VERSION ""

NS_ :

BS_:

BU_:

BO_ 1025 ID_1025: 8 Vector__XXX
 SG_ electricalRPM_FL_erpm : 7|32@0+ (1,0) [0|4294967295] "rpm" Vector__XXX
 SG_ dutyCycle_FL_percent : 39|16@0+ (0.1,0) [0.0|6553.5] "%" Vector__XXX
 SG_ inputInverterVoltage_FL_V : 55|16@0+ (1,0) [0|65535] "V" Vector__XXX

BO_ 1057 ID_1057: 8 Vector__XXX
 SG_ motorCurrent_FL_Apk : 7|16@0+ (0.1,0) [0.0|6553.5] "A" Vector__XXX
 SG_ batteryCurrent_FL_A : 23|16@0+ (0.1,0) [0.0|6553.5] "A" Vector__XXX

BO_ 1089 ID_1089: 8 Vector__XXX
 SG_ controllerTemp_FL_C : 7|16@0+ (0.1,0) [0.0|6553.5] "C" Vector__XXX
 SG_ motorTemp_FL_C : 23|16@0+ (0.1,0) [0.0|6553.5] "C" Vector__XXX
 SG_ faultCode_FL : 39|8@0+ (1,0) [0|255] "" Vector__XXX

BO_ 1121 ID_1121: 8 Vector__XXX
 SG_ idPeak_FL_A : 7|32@0+ (0.01,0) [0.0|42949672.95] "A" Vector__XXX
 SG_ iqPeak_FL_A : 39|32@0+ (0.01,0) [0.0|42949672.95] "A" Vector__XXX

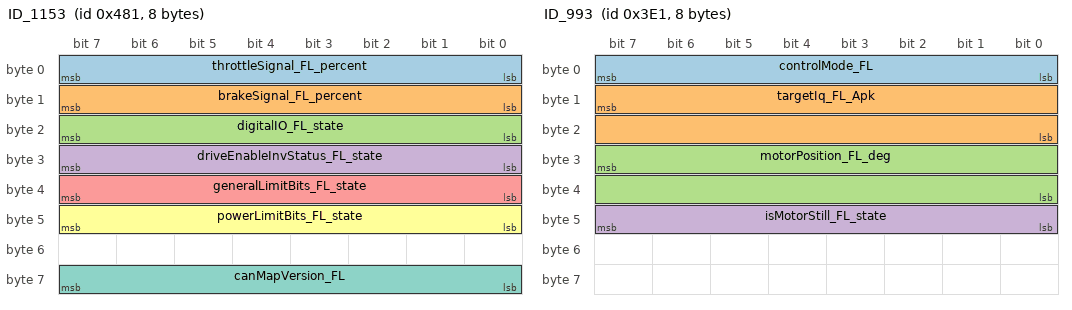
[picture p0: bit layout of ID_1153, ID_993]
BO_ 1153 ID_1153: 8 Vector__XXX
 SG_ throttleSignal_FL_percent : 7|8@0+ (1,0) [0|255] "%" Vector__XXX
 SG_ brakeSignal_FL_percent : 15|8@0+ (1,0) [0|255] "%" Vector__XXX
 SG_ digitalIO_FL_state : 23|8@0+ (1,0) [0|255] "" Vector__XXX
 SG_ driveEnableInvStatus_FL_state : 31|8@0+ (1,0) [0|255] "" Vector__XXX
 SG_ generalLimitBits_FL_state : 39|8@0+ (1,0) [0|255] "" Vector__XXX
 SG_ powerLimitBits_FL_state : 47|8@0+ (1,0) [0|255] "" Vector__XXX
 SG_ canMapVersion_FL : 63|8@0+ (1,0) [0|255] "" Vector__XXX

BO_ 993 ID_993: 8 Vector__XXX
 SG_ controlMode_FL : 7|8@0+ (1,0) [0|255] "" Vector__XXX
 SG_ targetIq_FL_Apk : 15|16@0+ (1,0) [0|65535] "Apk" Vector__XXX
 SG_ motorPosition_FL_deg : 31|16@0+ (1,0) [0|65535] "deg" Vector__XXX
 SG_ isMotorStill_FL_state : 47|8@0+ (1,0) [0|255] "" Vector__XXX

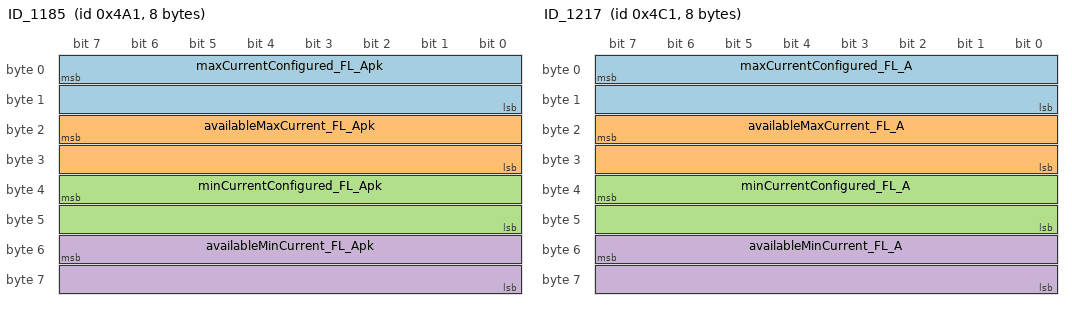
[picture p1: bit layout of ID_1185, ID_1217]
BO_ 1185 ID_1185: 8 Vector__XXX
 SG_ maxCurrentConfigured_FL_Apk : 7|16@0+ (0.1,0) [0.0|6553.5] "Apk" Vector__XXX
 SG_ availableMaxCurrent_FL_Apk : 23|16@0+ (0.1,0) [0.0|6553.5] "Apk" Vector__XXX
 SG_ minCurrentConfigured_FL_Apk : 39|16@0+ (0.1,0) [0.0|6553.5] "Apk" Vector__XXX
 SG_ availableMinCurrent_FL_Apk : 55|16@0+ (0.1,0) [0.0|6553.5] "Apk" Vector__XXX

BO_ 1217 ID_1217: 8 Vector__XXX
 SG_ maxCurrentConfigured_FL_A : 7|16@0+ (0.1,0) [0.0|6553.5] "A" Vector__XXX
 SG_ availableMaxCurrent_FL_A : 23|16@0+ (0.1,0) [0.0|6553.5] "A" Vector__XXX
 SG_ minCurrentConfigured_FL_A : 39|16@0+ (0.1,0) [0.0|6553.5] "A" Vector__XXX
 SG_ availableMinCurrent_FL_A : 55|16@0+ (0.1,0) [0.0|6553.5] "A" Vector__XXX

BO_ 33 ID_33: 8 Vector__XXX
 SG_ invCurrentCmd_FL_Apk : 7|16@0+ (0.1,0) [0.0|6553.5] "A" Vector__XXX

BO_ 257 ID_257: 8 Vector__XXX
 SG_ invMaxCurrentLimitCmd_FL_Apk : 7|16@0+ (0.1,0) [0.0|6553.5] "A" Vector__XXX

BO_ 321 ID_321: 8 Vector__XXX
 SG_ invMaxDCCurrentLimitCmd_FL_A : 7|16@0+ (0.1,0) [0.0|6553.5] "A" Vector__XXX

BO_ 385 ID_385: 8 Vector__XXX
 SG_ invDriveEnable_FL_state : 7|8@0+ (1,0) [0|255] "A" Vector__XXX

BO_ 1026 ID_1026: 8 Vector__XXX
 SG_ electricalRPM_FR_erpm : 7|32@0+ (1,0) [0|4294967295] "rpm" Vector__XXX
 SG_ dutyCycle_FR_percent : 39|16@0+ (0.1,0) [0.0|6553.5] "%" Vector__XXX
 SG_ inputInverterVoltage_FR_V : 55|16@0+ (1,0) [0|65535] "V" Vector__XXX

BO_ 1058 ID_1058: 8 Vector__XXX
 SG_ motorCurrent_FR_Apk : 7|16@0+ (0.1,0) [0.0|6553.5] "A" Vector__XXX
 SG_ batteryCurrent_FR_A : 23|16@0+ (0.1,0) [0.0|6553.5] "A" Vector__XXX

BO_ 1090 ID_1090: 8 Vector__XXX
 SG_ controllerTemp_FR_C : 7|16@0+ (0.1,0) [0.0|6553.5] "C" Vector__XXX
 SG_ motorTemp_FR_C : 23|16@0+ (0.1,0) [0.0|6553.5] "C" Vector__XXX
 SG_ faultCode_FR : 39|8@0+ (1,0) [0|255] "" Vector__XXX

BO_ 1122 ID_1122: 8 Vector__XXX
 SG_ idPeak_FR_A : 7|32@0+ (0.01,0) [0.0|42949672.95] "A" Vector__XXX
 SG_ iqPeak_FR_A : 39|32@0+ (0.01,0) [0.0|42949672.95] "A" Vector__XXX

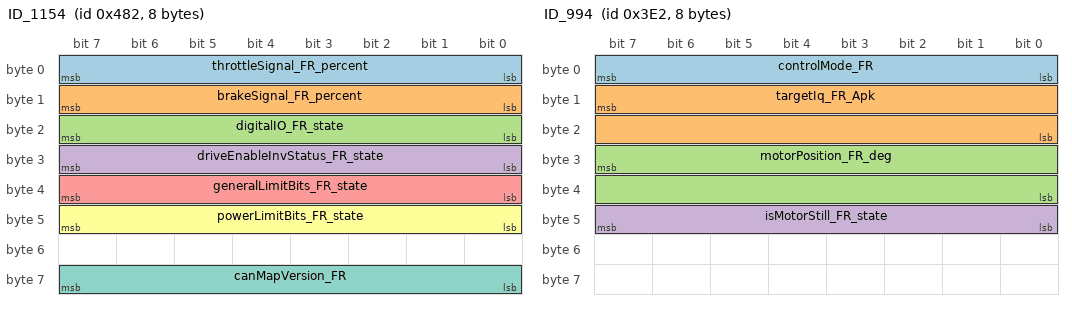
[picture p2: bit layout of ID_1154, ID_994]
BO_ 1154 ID_1154: 8 Vector__XXX
 SG_ throttleSignal_FR_percent : 7|8@0+ (1,0) [0|255] "%" Vector__XXX
 SG_ brakeSignal_FR_percent : 15|8@0+ (1,0) [0|255] "%" Vector__XXX
 SG_ digitalIO_FR_state : 23|8@0+ (1,0) [0|255] "" Vector__XXX
 SG_ driveEnableInvStatus_FR_state : 31|8@0+ (1,0) [0|255] "" Vector__XXX
 SG_ generalLimitBits_FR_state : 39|8@0+ (1,0) [0|255] "" Vector__XXX
 SG_ powerLimitBits_FR_state : 47|8@0+ (1,0) [0|255] "" Vector__XXX
 SG_ canMapVersion_FR : 63|8@0+ (1,0) [0|255] "" Vector__XXX

BO_ 994 ID_994: 8 Vector__XXX
 SG_ controlMode_FR : 7|8@0+ (1,0) [0|255] "" Vector__XXX
 SG_ targetIq_FR_Apk : 15|16@0+ (1,0) [0|65535] "Apk" Vector__XXX
 SG_ motorPosition_FR_deg : 31|16@0+ (1,0) [0|65535] "deg" Vector__XXX
 SG_ isMotorStill_FR_state : 47|8@0+ (1,0) [0|255] "" Vector__XXX

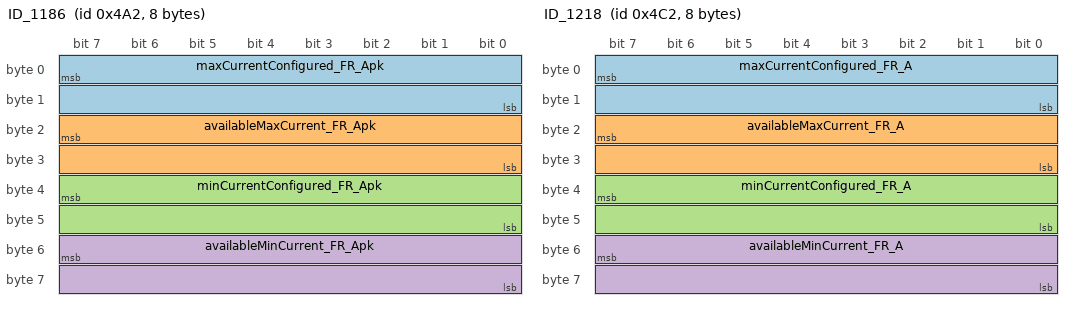
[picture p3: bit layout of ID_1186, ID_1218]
BO_ 1186 ID_1186: 8 Vector__XXX
 SG_ maxCurrentConfigured_FR_Apk : 7|16@0+ (0.1,0) [0.0|6553.5] "Apk" Vector__XXX
 SG_ availableMaxCurrent_FR_Apk : 23|16@0+ (0.1,0) [0.0|6553.5] "Apk" Vector__XXX
 SG_ minCurrentConfigured_FR_Apk : 39|16@0+ (0.1,0) [0.0|6553.5] "Apk" Vector__XXX
 SG_ availableMinCurrent_FR_Apk : 55|16@0+ (0.1,0) [0.0|6553.5] "Apk" Vector__XXX

BO_ 1218 ID_1218: 8 Vector__XXX
 SG_ maxCurrentConfigured_FR_A : 7|16@0+ (0.1,0) [0.0|6553.5] "A" Vector__XXX
 SG_ availableMaxCurrent_FR_A : 23|16@0+ (0.1,0) [0.0|6553.5] "A" Vector__XXX
 SG_ minCurrentConfigured_FR_A : 39|16@0+ (0.1,0) [0.0|6553.5] "A" Vector__XXX
 SG_ availableMinCurrent_FR_A : 55|16@0+ (0.1,0) [0.0|6553.5] "A" Vector__XXX

BO_ 34 ID_34: 8 Vector__XXX
 SG_ invCurrentCmd_FR_Apk : 7|16@0+ (0.1,0) [0.0|6553.5] "A" Vector__XXX

BO_ 258 ID_258: 8 Vector__XXX
 SG_ invMaxCurrentLimitCmd_FR_Apk : 7|16@0+ (0.1,0) [0.0|6553.5] "A" Vector__XXX

BO_ 322 ID_322: 8 Vector__XXX
 SG_ invMaxDCCurrentLimitCmd_FR_A : 7|16@0+ (0.1,0) [0.0|6553.5] "A" Vector__XXX

BO_ 386 ID_386: 8 Vector__XXX
 SG_ invDriveEnable_FR_state : 7|8@0+ (1,0) [0|255] "A" Vector__XXX

BO_ 1027 ID_1027: 8 Vector__XXX
 SG_ electricalRPM_RL_erpm : 7|32@0+ (1,0) [0|4294967295] "rpm" Vector__XXX
 SG_ dutyCycle_RL_percent : 39|16@0+ (0.1,0) [0.0|6553.5] "%" Vector__XXX
 SG_ inputInverterVoltage_RL_V : 55|16@0+ (1,0) [0|65535] "V" Vector__XXX

BO_ 1059 ID_1059: 8 Vector__XXX
 SG_ motorCurrent_RL_Apk : 7|16@0+ (0.1,0) [0.0|6553.5] "A" Vector__XXX
 SG_ batteryCurrent_RL_A : 23|16@0+ (0.1,0) [0.0|6553.5] "A" Vector__XXX

BO_ 1091 ID_1091: 8 Vector__XXX
 SG_ controllerTemp_RL_C : 7|16@0+ (0.1,0) [0.0|6553.5] "C" Vector__XXX
 SG_ motorTemp_RL_C : 23|16@0+ (0.1,0) [0.0|6553.5] "C" Vector__XXX
 SG_ faultCode_RL : 39|8@0+ (1,0) [0|255] "" Vector__XXX

BO_ 1123 ID_1123: 8 Vector__XXX
 SG_ idPeak_RL_A : 7|32@0+ (0.01,0) [0.0|42949672.95] "A" Vector__XXX
 SG_ iqPeak_RL_A : 39|32@0+ (0.01,0) [0.0|42949672.95] "A" Vector__XXX

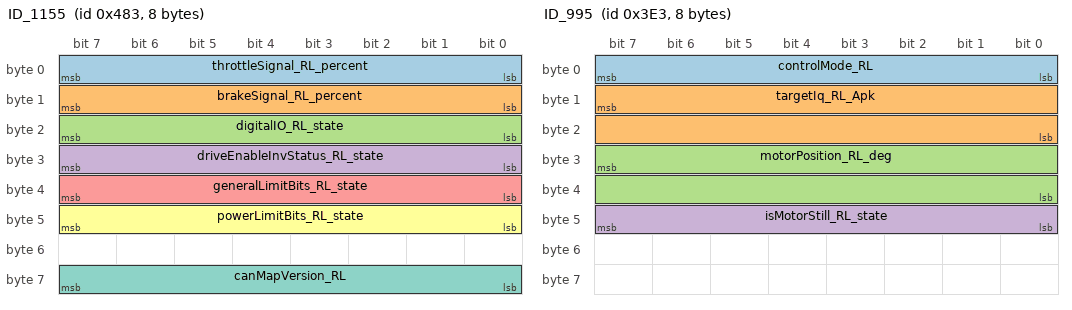
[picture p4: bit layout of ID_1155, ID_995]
BO_ 1155 ID_1155: 8 Vector__XXX
 SG_ throttleSignal_RL_percent : 7|8@0+ (1,0) [0|255] "%" Vector__XXX
 SG_ brakeSignal_RL_percent : 15|8@0+ (1,0) [0|255] "%" Vector__XXX
 SG_ digitalIO_RL_state : 23|8@0+ (1,0) [0|255] "" Vector__XXX
 SG_ driveEnableInvStatus_RL_state : 31|8@0+ (1,0) [0|255] "" Vector__XXX
 SG_ generalLimitBits_RL_state : 39|8@0+ (1,0) [0|255] "" Vector__XXX
 SG_ powerLimitBits_RL_state : 47|8@0+ (1,0) [0|255] "" Vector__XXX
 SG_ canMapVersion_RL : 63|8@0+ (1,0) [0|255] "" Vector__XXX

BO_ 995 ID_995: 8 Vector__XXX
 SG_ controlMode_RL : 7|8@0+ (1,0) [0|255] "" Vector__XXX
 SG_ targetIq_RL_Apk : 15|16@0+ (1,0) [0|65535] "Apk" Vector__XXX
 SG_ motorPosition_RL_deg : 31|16@0+ (1,0) [0|65535] "deg" Vector__XXX
 SG_ isMotorStill_RL_state : 47|8@0+ (1,0) [0|255] "" Vector__XXX

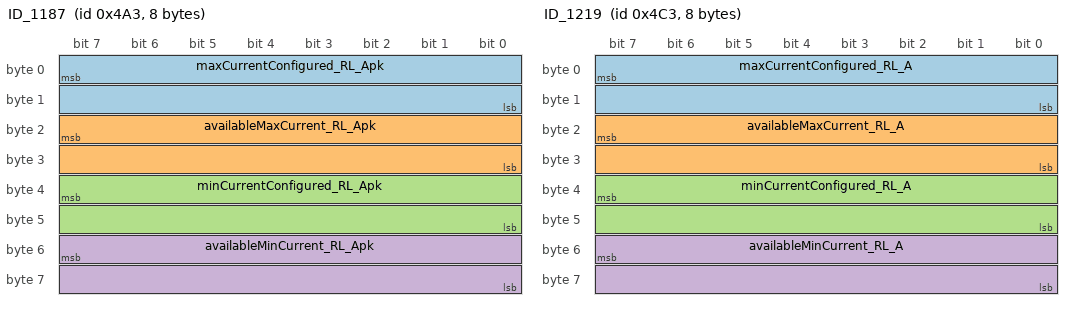
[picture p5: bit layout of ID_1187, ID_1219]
BO_ 1187 ID_1187: 8 Vector__XXX
 SG_ maxCurrentConfigured_RL_Apk : 7|16@0+ (0.1,0) [0.0|6553.5] "Apk" Vector__XXX
 SG_ availableMaxCurrent_RL_Apk : 23|16@0+ (0.1,0) [0.0|6553.5] "Apk" Vector__XXX
 SG_ minCurrentConfigured_RL_Apk : 39|16@0+ (0.1,0) [0.0|6553.5] "Apk" Vector__XXX
 SG_ availableMinCurrent_RL_Apk : 55|16@0+ (0.1,0) [0.0|6553.5] "Apk" Vector__XXX

BO_ 1219 ID_1219: 8 Vector__XXX
 SG_ maxCurrentConfigured_RL_A : 7|16@0+ (0.1,0) [0.0|6553.5] "A" Vector__XXX
 SG_ availableMaxCurrent_RL_A : 23|16@0+ (0.1,0) [0.0|6553.5] "A" Vector__XXX
 SG_ minCurrentConfigured_RL_A : 39|16@0+ (0.1,0) [0.0|6553.5] "A" Vector__XXX
 SG_ availableMinCurrent_RL_A : 55|16@0+ (0.1,0) [0.0|6553.5] "A" Vector__XXX

BO_ 35 ID_35: 8 Vector__XXX
 SG_ invCurrentCmd_RL_Apk : 7|16@0+ (0.1,0) [0.0|6553.5] "A" Vector__XXX

BO_ 259 ID_259: 8 Vector__XXX
 SG_ invMaxCurrentLimitCmd_RL_Apk : 7|16@0+ (0.1,0) [0.0|6553.5] "A" Vector__XXX

BO_ 323 ID_323: 8 Vector__XXX
 SG_ invMaxDCCurrentLimitCmd_RL_A : 7|16@0+ (0.1,0) [0.0|6553.5] "A" Vector__XXX

BO_ 387 ID_387: 8 Vector__XXX
 SG_ invDriveEnable_RL_state : 7|8@0+ (1,0) [0|255] "A" Vector__XXX

BO_ 1028 ID_1028: 8 Vector__XXX
 SG_ electricalRPM_RR_erpm : 7|32@0+ (1,0) [0|4294967295] "rpm" Vector__XXX
 SG_ dutyCycle_RR_percent : 39|16@0+ (0.1,0) [0.0|6553.5] "%" Vector__XXX
 SG_ inputInverterVoltage_RR_V : 55|16@0+ (1,0) [0|65535] "V" Vector__XXX

BO_ 1060 ID_1060: 8 Vector__XXX
 SG_ motorCurrent_RR_Apk : 7|16@0+ (0.1,0) [0.0|6553.5] "A" Vector__XXX
 SG_ batteryCurrent_RR_A : 23|16@0+ (0.1,0) [0.0|6553.5] "A" Vector__XXX

BO_ 1092 ID_1092: 8 Vector__XXX
 SG_ controllerTemp_RR_C : 7|16@0+ (0.1,0) [0.0|6553.5] "C" Vector__XXX
 SG_ motorTemp_RR_C : 23|16@0+ (0.1,0) [0.0|6553.5] "C" Vector__XXX
 SG_ faultCode_RR : 39|8@0+ (1,0) [0|255] "" Vector__XXX

BO_ 1124 ID_1124: 8 Vector__XXX
 SG_ idPeak_RR_A : 7|32@0+ (0.01,0) [0.0|42949672.95] "A" Vector__XXX
 SG_ iqPeak_RR_A : 39|32@0+ (0.01,0) [0.0|42949672.95] "A" Vector__XXX

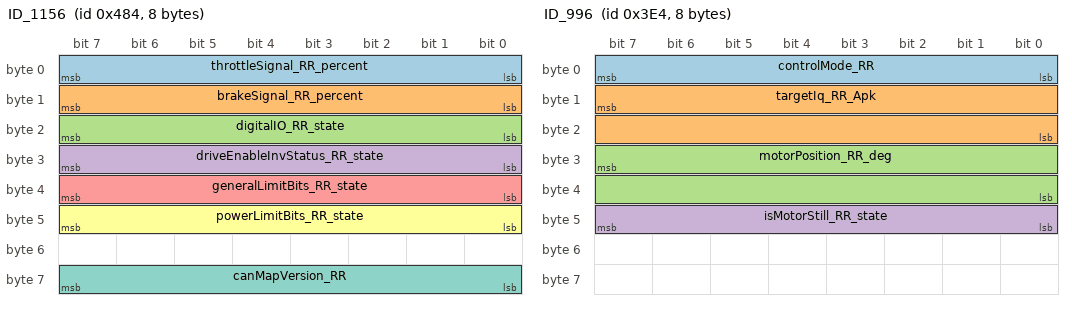
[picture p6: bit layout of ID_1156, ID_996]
BO_ 1156 ID_1156: 8 Vector__XXX
 SG_ throttleSignal_RR_percent : 7|8@0+ (1,0) [0|255] "%" Vector__XXX
 SG_ brakeSignal_RR_percent : 15|8@0+ (1,0) [0|255] "%" Vector__XXX
 SG_ digitalIO_RR_state : 23|8@0+ (1,0) [0|255] "" Vector__XXX
 SG_ driveEnableInvStatus_RR_state : 31|8@0+ (1,0) [0|255] "" Vector__XXX
 SG_ generalLimitBits_RR_state : 39|8@0+ (1,0) [0|255] "" Vector__XXX
 SG_ powerLimitBits_RR_state : 47|8@0+ (1,0) [0|255] "" Vector__XXX
 SG_ canMapVersion_RR : 63|8@0+ (1,0) [0|255] "" Vector__XXX

BO_ 996 ID_996: 8 Vector__XXX
 SG_ controlMode_RR : 7|8@0+ (1,0) [0|255] "" Vector__XXX
 SG_ targetIq_RR_Apk : 15|16@0+ (1,0) [0|65535] "Apk" Vector__XXX
 SG_ motorPosition_RR_deg : 31|16@0+ (1,0) [0|65535] "deg" Vector__XXX
 SG_ isMotorStill_RR_state : 47|8@0+ (1,0) [0|255] "" Vector__XXX

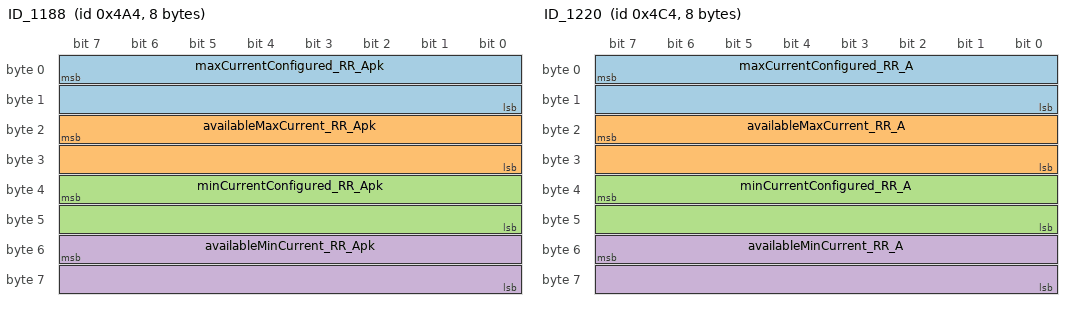
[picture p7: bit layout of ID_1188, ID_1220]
BO_ 1188 ID_1188: 8 Vector__XXX
 SG_ maxCurrentConfigured_RR_Apk : 7|16@0+ (0.1,0) [0.0|6553.5] "Apk" Vector__XXX
 SG_ availableMaxCurrent_RR_Apk : 23|16@0+ (0.1,0) [0.0|6553.5] "Apk" Vector__XXX
 SG_ minCurrentConfigured_RR_Apk : 39|16@0+ (0.1,0) [0.0|6553.5] "Apk" Vector__XXX
 SG_ availableMinCurrent_RR_Apk : 55|16@0+ (0.1,0) [0.0|6553.5] "Apk" Vector__XXX

BO_ 1220 ID_1220: 8 Vector__XXX
 SG_ maxCurrentConfigured_RR_A : 7|16@0+ (0.1,0) [0.0|6553.5] "A" Vector__XXX
 SG_ availableMaxCurrent_RR_A : 23|16@0+ (0.1,0) [0.0|6553.5] "A" Vector__XXX
 SG_ minCurrentConfigured_RR_A : 39|16@0+ (0.1,0) [0.0|6553.5] "A" Vector__XXX
 SG_ availableMinCurrent_RR_A : 55|16@0+ (0.1,0) [0.0|6553.5] "A" Vector__XXX

BO_ 36 ID_36: 8 Vector__XXX
 SG_ invCurrentCmd_RR_Apk : 7|16@0+ (0.1,0) [0.0|6553.5] "A" Vector__XXX

BO_ 260 ID_260: 8 Vector__XXX
 SG_ invMaxCurrentLimitCmd_RR_Apk : 7|16@0+ (0.1,0) [0.0|6553.5] "A" Vector__XXX

BO_ 324 ID_324: 8 Vector__XXX
 SG_ invMaxDCCurrentLimitCmd_RR_A : 7|16@0+ (0.1,0) [0.0|6553.5] "A" Vector__XXX

BO_ 388 ID_388: 8 Vector__XXX
 SG_ invDriveEnable_RR_state : 7|8@0+ (1,0) [0|255] "A" Vector__XXX

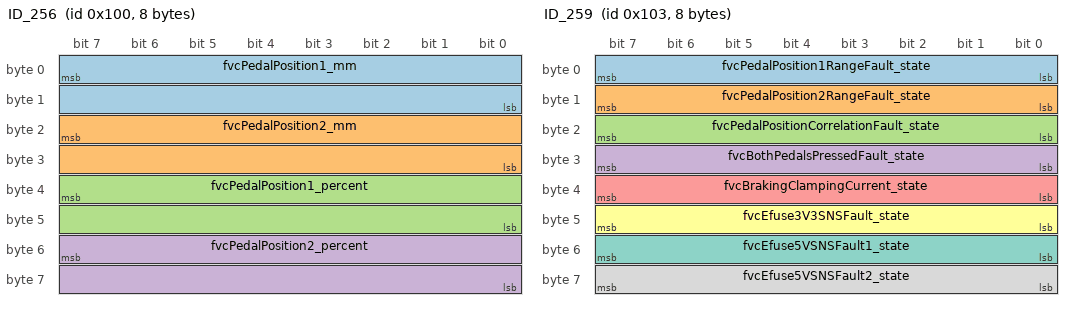
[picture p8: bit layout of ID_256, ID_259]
BO_ 256 ID_256: 8 Vector__XXX
 SG_ fvcPedalPosition1_mm : 7|16@0+ (0.00610500611,0) [0.0|400.09157541885] "mm" Vector__XXX
 SG_ fvcPedalPosition2_mm : 23|16@0+ (0.00610500611,0) [0.0|400.09157541885] "mm" Vector__XXX
 SG_ fvcPedalPosition1_percent : 39|16@0+ (0.1,0) [0.0|6553.5] "%" Vector__XXX
 SG_ fvcPedalPosition2_percent : 55|16@0+ (0.1,0) [0.0|6553.5] "%" Vector__XXX

BO_ 258 ID_258: 8 Vector__XXX
 SG_ fvcBrakePressureFront_psi : 7|16@0+ (0.488400488,0) [0.0|32007.32598108] "psi" Vector__XXX
 SG_ fvcBrakeTempFrontLeft_C : 23|16@0+ (0.195360195,0) [0.0|12802.930379324998] "C" Vector__XXX
 SG_ fvcBrakeTempFrontRight_C : 39|16@0+ (0.195360195,0) [0.0|12802.930379324998] "C" Vector__XXX

BO_ 259 ID_259: 8 Vector__XXX
 SG_ fvcPedalPosition1RangeFault_state : 7|8@0+ (1,0) [0|255] "" Vector__XXX
 SG_ fvcPedalPosition2RangeFault_state : 15|8@0+ (1,0) [0|255] "" Vector__XXX
 SG_ fvcPedalPositionCorrelationFault_state : 23|8@0+ (1,0) [0|255] "" Vector__XXX
 SG_ fvcBothPedalsPressedFault_state : 31|8@0+ (1,0) [0|255] "" Vector__XXX
 SG_ fvcBrakingClampingCurrent_state : 39|8@0+ (1,0) [0|255] "" Vector__XXX
 SG_ fvcEfuse3V3SNSFault_state : 47|8@0+ (1,0) [0|255] "ms" Vector__XXX
 SG_ fvcEfuse5VSNSFault1_state : 55|8@0+ (1,0) [0|255] "ms" Vector__XXX
 SG_ fvcEfuse5VSNSFault2_state : 63|8@0+ (1,0) [0|255] "ms" Vector__XXX

BO_ 260 ID_260: 8 Vector__XXX
 SG_ fvcDriveSpeedMode_state : 15|8@0+ (1,0) [0|255] "" Vector__XXX
 SG_ fvcMcuStatus_state : 23|8@0+ (1,0) [0|255] "" Vector__XXX
 SG_ fvcDisplayFaultStatus_state : 31|8@0+ (1,0) [0|255] "" Vector__XXX
 SG_ fvcSdcStatus3 : 39|8@0+ (1,0) [0|255] "" Vector__XXX
 SG_ fvcSdcStatus4 : 47|8@0+ (1,0) [0|255] "" Vector__XXX
 SG_ fvcEfuse5VSWMFault_state : 47|8@0+ (1,0) [0|255] "ms" Vector__XXX
 SG_ fvcEfuse12VSNSFault_state : 55|8@0+ (1,0) [0|255] "ms" Vector__XXX
 SG_ fvcEfuse12VDispFault_state : 63|8@0+ (1,0) [0|255] "ms" Vector__XXX

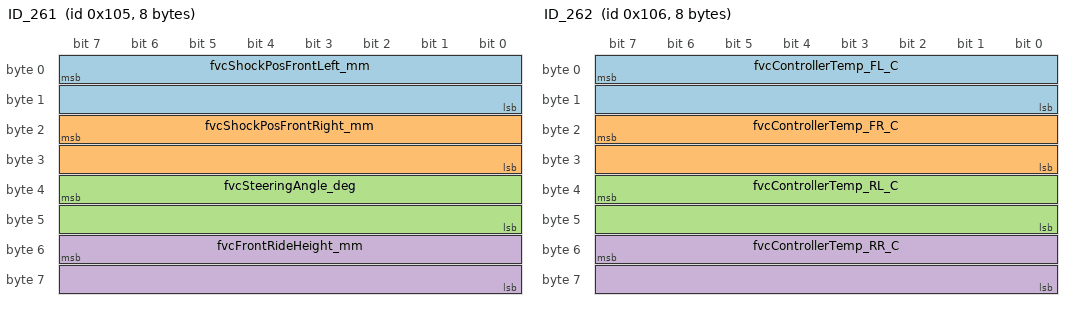
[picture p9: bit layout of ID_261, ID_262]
BO_ 261 ID_261: 8 Vector__XXX
 SG_ fvcShockPosFrontLeft_mm : 7|16@0+ (0.01221001221,0) [0.0|800.18315018235] "mm" Vector__XXX
 SG_ fvcShockPosFrontRight_mm : 23|16@0+ (0.01221001221,0) [0.0|800.18315018235] "mm" Vector__XXX
 SG_ fvcSteeringAngle_deg : 39|16@0+ (0.0879120879,0) [0.0|5761.3186805265] "deg" Vector__XXX
 SG_ fvcFrontRideHeight_mm : 55|16@0+ (1,0) [0|65535] "mm" Vector__XXX

BO_ 262 ID_262: 8 Vector__XXX
 SG_ fvcControllerTemp_FL_C : 7|16@0+ (0.1,0) [0.0|6553.5] "C" Vector__XXX
 SG_ fvcControllerTemp_FR_C : 23|16@0+ (0.1,0) [0.0|6553.5] "C" Vector__XXX
 SG_ fvcControllerTemp_RL_C : 39|16@0+ (0.1,0) [0.0|6553.5] "C" Vector__XXX
 SG_ fvcControllerTemp_RR_C : 55|16@0+ (0.1,0) [0.0|6553.5] "C" Vector__XXX

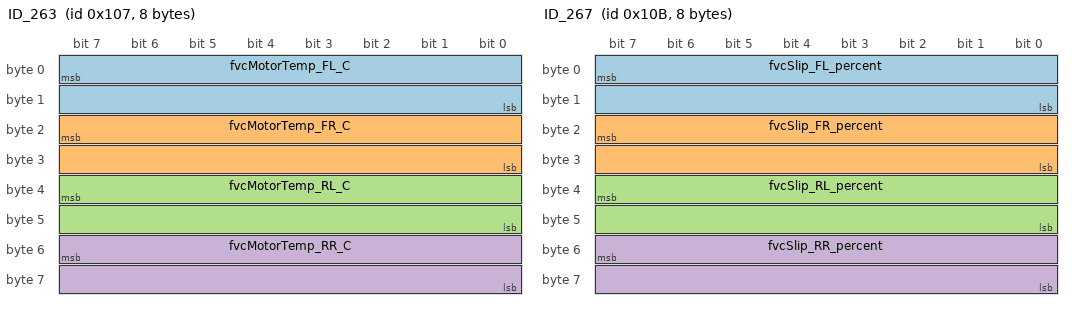
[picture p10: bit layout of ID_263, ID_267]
BO_ 263 ID_263: 8 Vector__XXX
 SG_ fvcMotorTemp_FL_C : 7|16@0+ (1,0) [0|65535] "C" Vector__XXX
 SG_ fvcMotorTemp_FR_C : 23|16@0+ (1,0) [0|65535] "C" Vector__XXX
 SG_ fvcMotorTemp_RL_C : 39|16@0+ (1,0) [0|65535] "C" Vector__XXX
 SG_ fvcMotorTemp_RR_C : 55|16@0+ (1,0) [0|65535] "C" Vector__XXX

BO_ 264 ID_264: 8 Vector__XXX
 SG_ fvcWheelSpeedFrontLeft_m_per_s : 7|32@0+ (0.001,0) [0.0|4294967.295] "mph" Vector__XXX
 SG_ fvcWheelSpeedFrontRight_m_per_s : 39|32@0+ (0.001,0) [0.0|4294967.295] "mph" Vector__XXX

BO_ 265 ID_265: 8 Vector__XXX
 SG_ fvcWheelSpeedRearLeft_m_per_s : 7|32@0+ (0.001,0) [0.0|4294967.295] "mph" Vector__XXX
 SG_ fvcWheelSpeedRearRight_m_per_s : 39|32@0+ (0.001,0) [0.0|4294967.295] "mph" Vector__XXX

BO_ 266 ID_266: 8 Vector__XXX
 SG_ fvcDriveControlTickStart_ms : 7|32@0+ (1,0) [0|4294967295] "ms" Vector__XXX
 SG_ fvcDriveControlTickEnd_ms : 39|32@0+ (1,0) [0|4294967295] "ms" Vector__XXX

BO_ 267 ID_267: 8 Vector__XXX
 SG_ fvcSlip_FL_percent : 7|16@0+ (1,0) [0|65535] "%" Vector__XXX
 SG_ fvcSlip_FR_percent : 23|16@0+ (1,0) [0|65535] "%" Vector__XXX
 SG_ fvcSlip_RL_percent : 39|16@0+ (1,0) [0|65535] "%" Vector__XXX
 SG_ fvcSlip_RR_percent : 55|16@0+ (1,0) [0|65535] "%" Vector__XXX

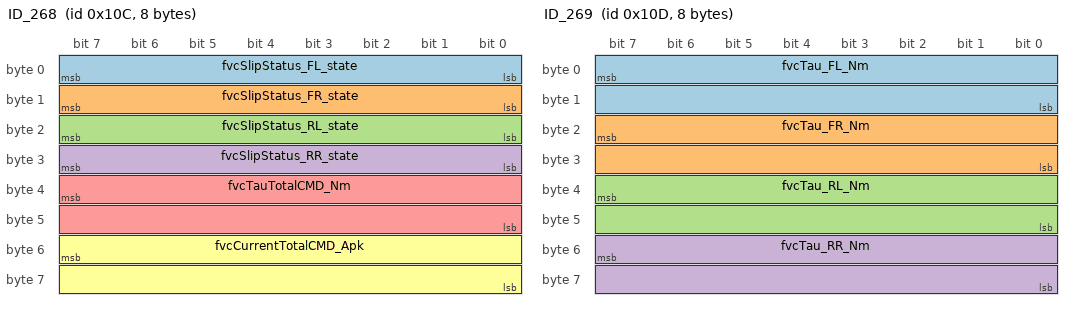
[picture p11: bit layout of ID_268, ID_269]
BO_ 268 ID_268: 8 Vector__XXX
 SG_ fvcSlipStatus_FL_state : 7|8@0+ (1,0) [0|255] "" Vector__XXX
 SG_ fvcSlipStatus_FR_state : 15|8@0+ (1,0) [0|255] "" Vector__XXX
 SG_ fvcSlipStatus_RL_state : 23|8@0+ (1,0) [0|255] "" Vector__XXX
 SG_ fvcSlipStatus_RR_state : 31|8@0+ (1,0) [0|255] "" Vector__XXX
 SG_ fvcTauTotalCMD_Nm : 39|16@0+ (1,0) [0|65535] "" Vector__XXX
 SG_ fvcCurrentTotalCMD_Apk : 55|16@0+ (1,0) [0|65535] "" Vector__XXX

BO_ 269 ID_269: 8 Vector__XXX
 SG_ fvcTau_FL_Nm : 7|16@0+ (1,0) [0|65535] "" Vector__XXX
 SG_ fvcTau_FR_Nm : 23|16@0+ (1,0) [0|65535] "" Vector__XXX
 SG_ fvcTau_RL_Nm : 39|16@0+ (1,0) [0|65535] "" Vector__XXX
 SG_ fvcTau_RR_Nm : 55|16@0+ (1,0) [0|65535] "" Vector__XXX

BO_ 270 ID_270: 8 Vector__XXX
 SG_ fvcSlipTractionLimit_percent : 7|16@0+ (1,0) [0|65535] "ms" Vector__XXX
 SG_ fvcVehicleState_state : 23|8@0+ (1,0) [0|255] "" Vector__XXX

BO_ 271 ID_271: 8 Vector__XXX
 SG_ fvcEfuse12VDispCurrent_A : 7|16@0+ (0.00123028083,0) [0.0|80.62645419405] "ms" Vector__XXX
 SG_ fvcEfuse12VSNSCurrent_A : 23|16@0+ (0.00019780219,0) [0.0|12.96296652165] "ms" Vector__XXX

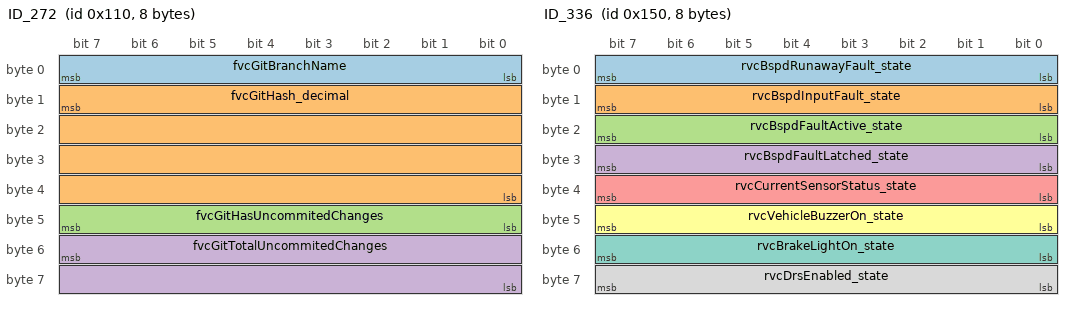
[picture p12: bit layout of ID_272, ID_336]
BO_ 272 ID_272: 8 Vector__XXX
 SG_ fvcGitBranchName : 7|8@0+ (1,0) [0|255] "ms" Vector__XXX
 SG_ fvcGitHash_decimal : 15|32@0+ (1,0) [0|4294967295] "ms" Vector__XXX
 SG_ fvcGitHasUncommitedChanges : 47|8@0+ (1,0) [0|255] "ms" Vector__XXX
 SG_ fvcGitTotalUncommitedChanges : 55|16@0+ (1,0) [0|65535] "ms" Vector__XXX

BO_ 336 ID_336: 8 Vector__XXX
 SG_ rvcBspdRunawayFault_state : 7|8@0+ (1,0) [0|255] "" Vector__XXX
 SG_ rvcBspdInputFault_state : 15|8@0+ (1,0) [0|255] "" Vector__XXX
 SG_ rvcBspdFaultActive_state : 23|8@0+ (1,0) [0|255] "" Vector__XXX
 SG_ rvcBspdFaultLatched_state : 31|8@0+ (1,0) [0|255] "" Vector__XXX
 SG_ rvcCurrentSensorStatus_state : 39|8@0+ (1,0) [0|255] "A" Vector__XXX
 SG_ rvcVehicleBuzzerOn_state : 47|8@0+ (1,0) [0|255] "" Vector__XXX
 SG_ rvcBrakeLightOn_state : 55|8@0+ (1,0) [0|255] "" Vector__XXX
 SG_ rvcDrsEnabled_state : 63|8@0+ (1,0) [0|255] "" Vector__XXX

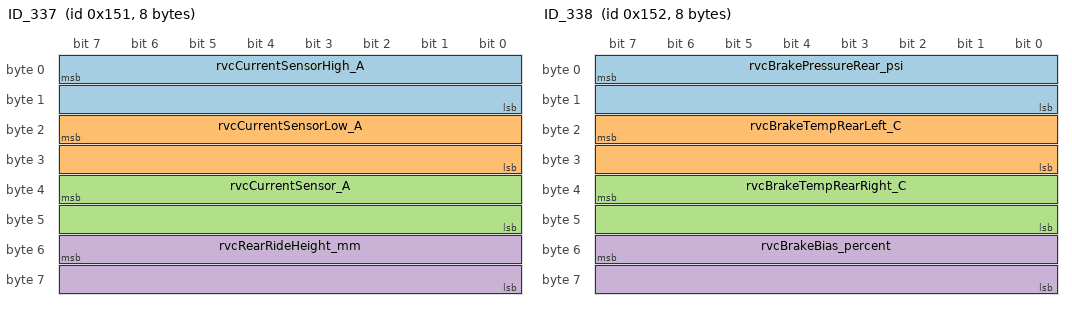
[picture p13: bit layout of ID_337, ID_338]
BO_ 337 ID_337: 8 Vector__XXX
 SG_ rvcCurrentSensorHigh_A : 7|16@0+ (0.1,-1000) [-1000.0|5553.5] "V" Vector__XXX
 SG_ rvcCurrentSensorLow_A : 23|16@0+ (0.01,-100) [-100.0|555.35] "V" Vector__XXX
 SG_ rvcCurrentSensor_A : 39|16@0+ (0.01414511329,75) [75.0|1001.99999946015] "A" Vector__XXX
 SG_ rvcRearRideHeight_mm : 55|16@0+ (1,0) [0|65535] "mm" Vector__XXX

BO_ 338 ID_338: 8 Vector__XXX
 SG_ rvcBrakePressureRear_psi : 7|16@0+ (0.488400488,0) [0.0|32007.32598108] "psi" Vector__XXX
 SG_ rvcBrakeTempRearLeft_C : 23|16@0+ (0.195360195,0) [0.0|12802.930379324998] "C" Vector__XXX
 SG_ rvcBrakeTempRearRight_C : 39|16@0+ (0.195360195,0) [0.0|12802.930379324998] "C" Vector__XXX
 SG_ rvcBrakeBias_percent : 55|16@0+ (1,0) [0|65535] "" Vector__XXX

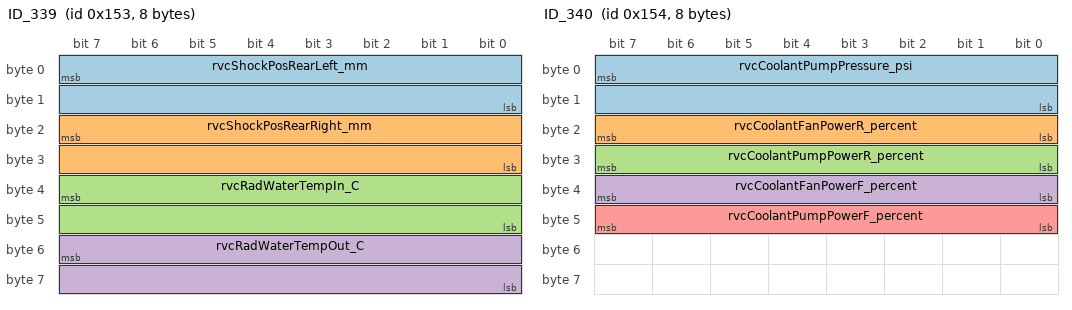
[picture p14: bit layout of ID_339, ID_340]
BO_ 339 ID_339: 8 Vector__XXX
 SG_ rvcShockPosRearLeft_mm : 7|16@0+ (0.01221001221,0) [0.0|800.18315018235] "mm" Vector__XXX
 SG_ rvcShockPosRearRight_mm : 23|16@0+ (0.01221001221,0) [0.0|800.18315018235] "mm" Vector__XXX
 SG_ rvcRadWaterTempIn_C : 39|16@0+ (0.0488400488,0) [0.0|3200.7325981080003] "C" Vector__XXX
 SG_ rvcRadWaterTempOut_C : 55|16@0+ (0.0488400488,0) [0.0|3200.7325981080003] "C" Vector__XXX

BO_ 340 ID_340: 8 Vector__XXX
 SG_ rvcCoolantPumpPressure_psi : 7|16@0+ (0.0244200244,0) [0.0|1600.3662990540001] "psi" Vector__XXX
 SG_ rvcCoolantFanPowerR_percent : 23|8@0+ (1,0) [0|255] "%" Vector__XXX
 SG_ rvcCoolantPumpPowerR_percent : 31|8@0+ (1,0) [0|255] "%" Vector__XXX
 SG_ rvcCoolantFanPowerF_percent : 39|8@0+ (1,0) [0|255] "%" Vector__XXX
 SG_ rvcCoolantPumpPowerF_percent : 47|8@0+ (1,0) [0|255] "%" Vector__XXX

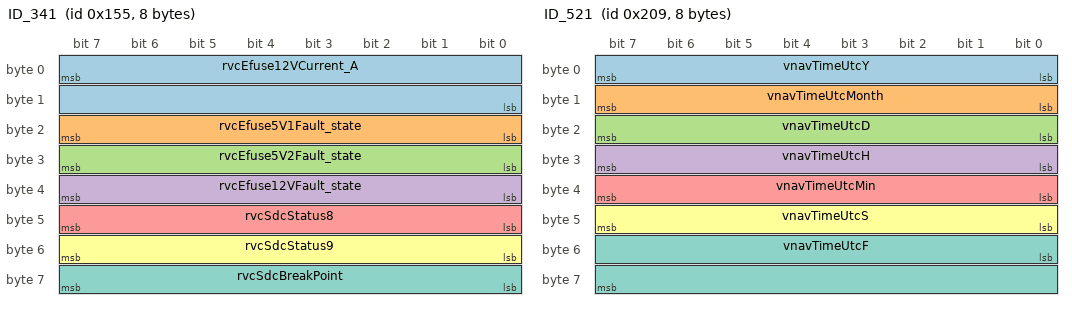
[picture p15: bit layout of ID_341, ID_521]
BO_ 341 ID_341: 8 Vector__XXX
 SG_ rvcEfuse12VCurrent_A : 7|16@0+ (0.000244200244,0) [0.0|16.003662990539997] "A" Vector__XXX
 SG_ rvcEfuse5V1Fault_state : 23|8@0+ (1,0) [0|255] "" Vector__XXX
 SG_ rvcEfuse5V2Fault_state : 31|8@0+ (1,0) [0|255] "" Vector__XXX
 SG_ rvcEfuse12VFault_state : 39|8@0+ (1,0) [0|255] "" Vector__XXX
 SG_ rvcSdcStatus8 : 47|8@0+ (1,0) [0|255] "" Vector__XXX
 SG_ rvcSdcStatus9 : 55|8@0+ (1,0) [0|255] "" Vector__XXX
 SG_ rvcSdcBreakPoint : 63|8@0+ (1,0) [0|255] "" Vector__XXX

BO_ 512 ID_512: 8 Vector__XXX
 SG_ vnavLatitude : 0|64@1+ (9.75781955236954e-18,-90) [-90.0|90.0] "deg" Vector__XXX

BO_ 513 ID_513: 8 Vector__XXX
 SG_ vnavLongitude : 0|64@1+ (1.951563910473908e-17,-180) [-180.0|180.0] "deg" Vector__XXX

BO_ 514 ID_514: 8 Vector__XXX
 SG_ vnavAltitude : 0|64@1+ (2.710505431213761e-16,-1000) [-1000.0|4000.0] "m" Vector__XXX

BO_ 515 ID_515: 8 Vector__XXX
 SG_ vnavVelBodyX : 0|32@1+ (3.2596290116e-08,-70) [-70.0|69.99999998655176] "m/s" Vector__XXX
 SG_ vnavVelBodyY : 32|32@1+ (3.2596290116e-08,-70) [-70.0|69.99999998655176] "m/s" Vector__XXX

BO_ 516 ID_516: 8 Vector__XXX
 SG_ vnavYaw : 0|32@1+ (8.3819031728e-08,-180) [-180.0|179.99999997032734] "deg" Vector__XXX
 SG_ vnavPitch : 32|32@1+ (4.1909515864e-08,-90) [-90.0|89.99999998516367] "deg" Vector__XXX

BO_ 517 ID_517: 8 Vector__XXX
 SG_ vnavRoll : 0|32@1+ (8.3819031728e-08,-180) [-180.0|179.99999997032734] "deg" Vector__XXX
 SG_ vnavLinBodyAccZ : 32|32@1+ (2.3283064375e-08,-50) [-50.0|50.00000001800461] "m/s^2" Vector__XXX

BO_ 518 ID_518: 8 Vector__XXX
 SG_ vnavLinBodyAccX : 0|32@1+ (2.3283064375e-08,-50) [-50.0|50.00000001800461] "m/s^2" Vector__XXX
 SG_ vnavLinBodyAccY : 32|32@1+ (2.3283064375e-08,-50) [-50.0|50.00000001800461] "m/s^2" Vector__XXX

BO_ 519 ID_519: 8 Vector__XXX
 SG_ vnavQuatX : 0|32@1+ (4.65661287524e-10,-1) [-1.0|1.0000000004631717] "none" Vector__XXX
 SG_ vnavQuatY : 32|32@1+ (4.65661287524e-10,-1) [-1.0|1.0000000004631717] "none" Vector__XXX

BO_ 520 ID_520: 8 Vector__XXX
 SG_ vnavQuatZ : 0|32@1+ (4.65661287524e-10,-1) [-1.0|1.0000000004631717] "none" Vector__XXX
 SG_ vnavQuatS : 32|32@1+ (4.65661287524e-10,-1) [-1.0|1.0000000004631717] "none" Vector__XXX

BO_ 521 ID_521: 8 Vector__XXX
 SG_ vnavTimeUtcY : 0|8@1+ (1,0) [0|255] "none" Vector__XXX
 SG_ vnavTimeUtcMonth : 8|8@1+ (1,0) [0|255] "none" Vector__XXX
 SG_ vnavTimeUtcD : 16|8@1+ (1,0) [0|255] "none" Vector__XXX
 SG_ vnavTimeUtcH : 24|8@1+ (1,0) [0|255] "none" Vector__XXX
 SG_ vnavTimeUtcMin : 32|8@1+ (1,0) [0|255] "none" Vector__XXX
 SG_ vnavTimeUtcS : 40|8@1+ (1,0) [0|255] "none" Vector__XXX
 SG_ vnavTimeUtcF : 48|16@1+ (1,0) [0|65535] "none" Vector__XXX

BO_ 522 ID_522: 8 Vector__XXX
 SG_ vnavGyroBodyX : 0|32@1+ (9.31322574847e-07,-2000) [-2000.0|2000.0000000630548] "deg/s" Vector__XXX
 SG_ vnavGyroBodyY : 32|32@1+ (9.31322574847e-07,-2000) [-2000.0|2000.0000000630548] "deg/s" Vector__XXX

BO_ 523 ID_523: 8 Vector__XXX
 SG_ vnavGyroBodyZ : 0|32@1+ (9.31322574847e-07,-2000) [-2000.0|2000.0000000630548] "deg/s" Vector__XXX
 SG_ vnavINS_status : 32|16@1+ (1,0) [0|65535] "none" Vector__XXX

BO_ 524 ID_524: 8 Vector__XXX
 SG_ vnavVelBodyZ : 0|32@1+ (3.2596290116e-08,-70) [-70.0|69.99999998655176] "m/s" Vector__XXX

BO_ 592 ID_592: 8 Vector__XXX
 SG_ swButon0_state : 39|8@0+ (1,0) [0|255] "" Vector__XXX
 SG_ swButon1_state : 47|8@0+ (1,0) [0|255] "" Vector__XXX
 SG_ displayPage_state : 55|8@0+ (1,0) [0|255] "" Vector__XXX

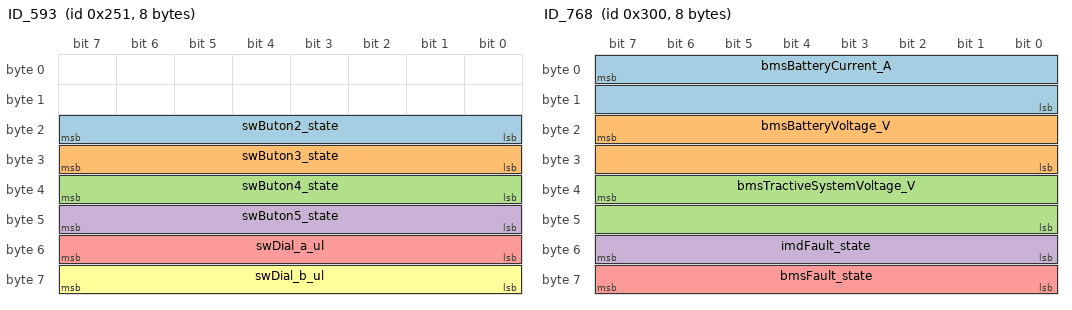
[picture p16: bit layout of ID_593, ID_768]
BO_ 593 ID_593: 8 Vector__XXX
 SG_ swButon2_state : 23|8@0+ (1,0) [0|255] "" Vector__XXX
 SG_ swButon3_state : 31|8@0+ (1,0) [0|255] "" Vector__XXX
 SG_ swButon4_state : 39|8@0+ (1,0) [0|255] "" Vector__XXX
 SG_ swButon5_state : 47|8@0+ (1,0) [0|255] "" Vector__XXX
 SG_ swDial_a_ul : 55|8@0+ (1,0) [0|255] "" Vector__XXX
 SG_ swDial_b_ul : 63|8@0+ (1,0) [0|255] "" Vector__XXX

BO_ 768 ID_768: 8 Vector__XXX
 SG_ bmsBatteryCurrent_A : 7|16@0+ (0.01,-300) [-300.0|355.35] "A" Vector__XXX
 SG_ bmsBatteryVoltage_V : 23|16@0+ (0.1,0) [0.0|6553.5] "V" Vector__XXX
 SG_ bmsTractiveSystemVoltage_V : 39|16@0+ (0.1,0) [0.0|6553.5] "V" Vector__XXX
 SG_ imdFault_state : 55|8@0+ (1,0) [0|255] "" Vector__XXX
 SG_ bmsFault_state : 63|8@0+ (1,0) [0|255] "" Vector__XXX

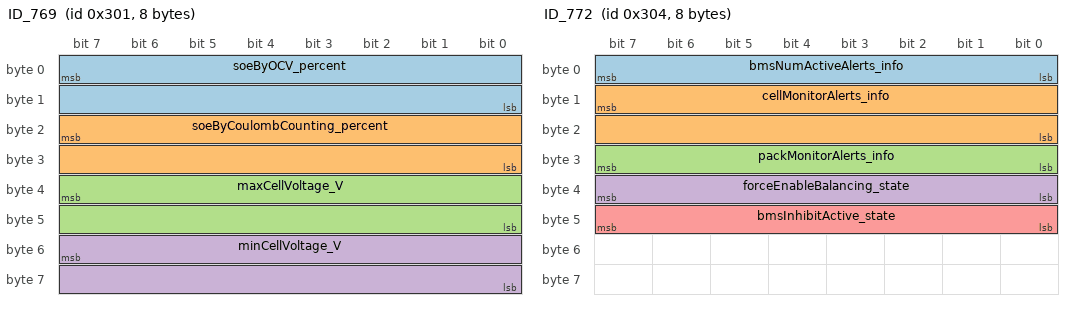
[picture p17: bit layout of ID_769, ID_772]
BO_ 769 ID_769: 8 Vector__XXX
 SG_ soeByOCV_percent : 7|16@0+ (0.01,0) [0.0|655.35] "%" Vector__XXX
 SG_ soeByCoulombCounting_percent : 23|16@0+ (0.01,0) [0.0|655.35] "%" Vector__XXX
 SG_ maxCellVoltage_V : 39|16@0+ (0.01,0) [0.0|655.35] "V" Vector__XXX
 SG_ minCellVoltage_V : 55|16@0+ (0.01,0) [0.0|655.35] "V" Vector__XXX

BO_ 770 ID_770: 8 Vector__XXX
 SG_ avgCellVoltage_V : 7|16@0+ (0.01,0) [0.0|655.35] "V" Vector__XXX
 SG_ cellImbalance_mV : 23|16@0+ (0.1,0) [0.0|6553.5] "mV" Vector__XXX
 SG_ maxCellTemp_C : 39|16@0+ (0.1,-40) [-40.0|6513.5] "C" Vector__XXX
 SG_ minCellTemp_C : 55|16@0+ (0.1,-40) [-40.0|6513.5] "C" Vector__XXX

BO_ 771 ID_771: 8 Vector__XXX
 SG_ avgCellTemp_C : 7|16@0+ (0.1,-40) [-40.0|6513.5] "C" Vector__XXX
 SG_ maxBoardTemp_C : 23|16@0+ (0.1,-40) [-40.0|6513.5] "C" Vector__XXX
 SG_ minBoardTemp_C : 39|16@0+ (0.1,-40) [-40.0|6513.5] "C" Vector__XXX
 SG_ avgBoardTemp_C : 55|16@0+ (0.1,-40) [-40.0|6513.5] "C" Vector__XXX

BO_ 772 ID_772: 8 Vector__XXX
 SG_ bmsNumActiveAlerts_info : 7|8@0+ (1,0) [0|255] "" Vector__XXX
 SG_ cellMonitorAlerts_info : 15|16@0+ (1,0) [0|65535] "" Vector__XXX
 SG_ packMonitorAlerts_info : 31|8@0+ (1,0) [0|255] "" Vector__XXX
 SG_ forceEnableBalancing_state : 39|8@0+ (1,0) [0|255] "" Vector__XXX
 SG_ bmsInhibitActive_state : 47|8@0+ (1,0) [0|255] "" Vector__XXX

BO_ 784 ID_784: 8 Vector__XXX
 SG_ module1MaxCellVoltage_V : 7|16@0+ (0.001,0) [0.0|65.535] "V" Vector__XXX
 SG_ module1MinCellVoltage_V : 23|16@0+ (0.001,0) [0.0|65.535] "V" Vector__XXX
 SG_ module1AvgCellVoltage_V : 39|16@0+ (0.001,0) [0.0|65.535] "V" Vector__XXX
 SG_ module1DieTemperature_C : 55|16@0+ (0.1,-40) [-40.0|6513.5] "C" Vector__XXX

BO_ 785 ID_785: 8 Vector__XXX
 SG_ module1MaxCellTemperature_C : 7|16@0+ (0.1,-40) [-40.0|6513.5] "C" Vector__XXX
 SG_ module1MinCellTemperature_C : 23|16@0+ (0.1,-40) [-40.0|6513.5] "C" Vector__XXX
 SG_ module1AvgCellTemperature_C : 39|16@0+ (0.1,-40) [-40.0|6513.5] "C" Vector__XXX
 SG_ module1BoardTemperature_C : 55|16@0+ (0.1,-40) [-40.0|6513.5] "C" Vector__XXX

BO_ 786 ID_786: 8 Vector__XXX
 SG_ module1Cell1Voltage_V : 7|16@0+ (0.001,0) [0.0|65.535] "V" Vector__XXX
 SG_ module1Cell2Voltage_V : 23|16@0+ (0.001,0) [0.0|65.535] "V" Vector__XXX
 SG_ module1Cell3Voltage_V : 39|16@0+ (0.001,0) [0.0|65.535] "V" Vector__XXX
 SG_ module1Cell4Voltage_V : 55|16@0+ (0.001,0) [0.0|65.535] "V" Vector__XXX

BO_ 787 ID_787: 8 Vector__XXX
 SG_ module1Cell5Voltage_V : 7|16@0+ (0.001,0) [0.0|65.535] "V" Vector__XXX
 SG_ module1Cell6Voltage_V : 23|16@0+ (0.001,0) [0.0|65.535] "V" Vector__XXX
 SG_ module1Cell7Voltage_V : 39|16@0+ (0.001,0) [0.0|65.535] "V" Vector__XXX
 SG_ module1Cell8Voltage_V : 55|16@0+ (0.001,0) [0.0|65.535] "V" Vector__XXX

BO_ 788 ID_788: 8 Vector__XXX
 SG_ module1Cell9Voltage_V : 7|16@0+ (0.001,0) [0.0|65.535] "V" Vector__XXX
 SG_ module1Cell10Voltage_V : 23|16@0+ (0.001,0) [0.0|65.535] "V" Vector__XXX
 SG_ module1Cell11Voltage_V : 39|16@0+ (0.001,0) [0.0|65.535] "V" Vector__XXX
 SG_ module1Cell12Voltage_V : 55|16@0+ (0.001,0) [0.0|65.535] "V" Vector__XXX

BO_ 789 ID_789: 8 Vector__XXX
 SG_ module1Cell13Voltage_V : 7|16@0+ (0.001,0) [0.0|65.535] "V" Vector__XXX
 SG_ module1Cell14Voltage_V : 23|16@0+ (0.001,0) [0.0|65.535] "V" Vector__XXX
 SG_ module1Cell1Temperature_C : 39|16@0+ (0.1,-40) [-40.0|6513.5] "C" Vector__XXX
 SG_ module1Cell2Temperature_C : 55|16@0+ (0.1,-40) [-40.0|6513.5] "C" Vector__XXX

BO_ 790 ID_790: 8 Vector__XXX
 SG_ module1Cell3Temperature_C : 7|16@0+ (0.1,-40) [-40.0|6513.5] "C" Vector__XXX
 SG_ module1Cell4Temperature_C : 23|16@0+ (0.1,-40) [-40.0|6513.5] "C" Vector__XXX
 SG_ module1Cell5Temperature_C : 39|16@0+ (0.1,-40) [-40.0|6513.5] "C" Vector__XXX
 SG_ module1Cell6Temperature_C : 55|16@0+ (0.1,-40) [-40.0|6513.5] "C" Vector__XXX

BO_ 791 ID_791: 8 Vector__XXX
 SG_ module1Cell7Temperature_C : 7|16@0+ (0.1,-40) [-40.0|6513.5] "C" Vector__XXX
 SG_ module1Cell8Temperature_C : 23|16@0+ (0.1,-40) [-40.0|6513.5] "C" Vector__XXX
 SG_ module1Cell9Temperature_C : 39|16@0+ (0.1,-40) [-40.0|6513.5] "C" Vector__XXX
 SG_ module1Cell10Temperature_C : 55|16@0+ (0.1,-40) [-40.0|6513.5] "C" Vector__XXX

BO_ 792 ID_792: 8 Vector__XXX
 SG_ module1Cell11Temperature_C : 7|16@0+ (0.1,-40) [-40.0|6513.5] "C" Vector__XXX
 SG_ module1Cell12Temperature_C : 23|16@0+ (0.1,-40) [-40.0|6513.5] "C" Vector__XXX
 SG_ module1Cell13Temperature_C : 39|16@0+ (0.1,-40) [-40.0|6513.5] "C" Vector__XXX
 SG_ module1Cell14Temperature_C : 55|16@0+ (0.1,-40) [-40.0|6513.5] "C" Vector__XXX

BO_ 800 ID_800: 8 Vector__XXX
 SG_ module2MaxCellVoltage_V : 7|16@0+ (0.001,0) [0.0|65.535] "V" Vector__XXX
 SG_ module2MinCellVoltage_V : 23|16@0+ (0.001,0) [0.0|65.535] "V" Vector__XXX
 SG_ module2AvgCellVoltage_V : 39|16@0+ (0.001,0) [0.0|65.535] "V" Vector__XXX
 SG_ module2DieTemperature_C : 55|16@0+ (0.1,-40) [-40.0|6513.5] "C" Vector__XXX

BO_ 801 ID_801: 8 Vector__XXX
 SG_ module2MaxCellTemperature_C : 7|16@0+ (0.1,-40) [-40.0|6513.5] "C" Vector__XXX
 SG_ module2MinCellTemperature_C : 23|16@0+ (0.1,-40) [-40.0|6513.5] "C" Vector__XXX
 SG_ module2AvgCellTemperature_C : 39|16@0+ (0.1,-40) [-40.0|6513.5] "C" Vector__XXX
 SG_ module2BoardTemperature_C : 55|16@0+ (0.1,-40) [-40.0|6513.5] "C" Vector__XXX

BO_ 802 ID_802: 8 Vector__XXX
 SG_ module2Cell1Voltage_V : 7|16@0+ (0.001,0) [0.0|65.535] "V" Vector__XXX
 SG_ module2Cell2Voltage_V : 23|16@0+ (0.001,0) [0.0|65.535] "V" Vector__XXX
 SG_ module2Cell3Voltage_V : 39|16@0+ (0.001,0) [0.0|65.535] "V" Vector__XXX
 SG_ module2Cell4Voltage_V : 55|16@0+ (0.001,0) [0.0|65.535] "V" Vector__XXX

BO_ 803 ID_803: 8 Vector__XXX
 SG_ module2Cell5Voltage_V : 7|16@0+ (0.001,0) [0.0|65.535] "V" Vector__XXX
 SG_ module2Cell6Voltage_V : 23|16@0+ (0.001,0) [0.0|65.535] "V" Vector__XXX
 SG_ module2Cell7Voltage_V : 39|16@0+ (0.001,0) [0.0|65.535] "V" Vector__XXX
 SG_ module2Cell8Voltage_V : 55|16@0+ (0.001,0) [0.0|65.535] "V" Vector__XXX

BO_ 804 ID_804: 8 Vector__XXX
 SG_ module2Cell9Voltage_V : 7|16@0+ (0.001,0) [0.0|65.535] "V" Vector__XXX
 SG_ module2Cell10Voltage_V : 23|16@0+ (0.001,0) [0.0|65.535] "V" Vector__XXX
 SG_ module2Cell11Voltage_V : 39|16@0+ (0.001,0) [0.0|65.535] "V" Vector__XXX
 SG_ module2Cell12Voltage_V : 55|16@0+ (0.001,0) [0.0|65.535] "V" Vector__XXX

BO_ 805 ID_805: 8 Vector__XXX
 SG_ module2Cell13Voltage_V : 7|16@0+ (0.001,0) [0.0|65.535] "V" Vector__XXX
 SG_ module2Cell14Voltage_V : 23|16@0+ (0.001,0) [0.0|65.535] "V" Vector__XXX
 SG_ module2Cell1Temperature_C : 39|16@0+ (0.1,-40) [-40.0|6513.5] "C" Vector__XXX
 SG_ module2Cell2Temperature_C : 55|16@0+ (0.1,-40) [-40.0|6513.5] "C" Vector__XXX

BO_ 806 ID_806: 8 Vector__XXX
 SG_ module2Cell3Temperature_C : 7|16@0+ (0.1,-40) [-40.0|6513.5] "C" Vector__XXX
 SG_ module2Cell4Temperature_C : 23|16@0+ (0.1,-40) [-40.0|6513.5] "C" Vector__XXX
 SG_ module2Cell5Temperature_C : 39|16@0+ (0.1,-40) [-40.0|6513.5] "C" Vector__XXX
 SG_ module2Cell6Temperature_C : 55|16@0+ (0.1,-40) [-40.0|6513.5] "C" Vector__XXX

BO_ 807 ID_807: 8 Vector__XXX
 SG_ module2Cell7Temperature_C : 7|16@0+ (0.1,-40) [-40.0|6513.5] "C" Vector__XXX
 SG_ module2Cell8Temperature_C : 23|16@0+ (0.1,-40) [-40.0|6513.5] "C" Vector__XXX
 SG_ module2Cell9Temperature_C : 39|16@0+ (0.1,-40) [-40.0|6513.5] "C" Vector__XXX
 SG_ module2Cell10Temperature_C : 55|16@0+ (0.1,-40) [-40.0|6513.5] "C" Vector__XXX

BO_ 808 ID_808: 8 Vector__XXX
 SG_ module2Cell11Temperature_C : 7|16@0+ (0.1,-40) [-40.0|6513.5] "C" Vector__XXX
 SG_ module2Cell12Temperature_C : 23|16@0+ (0.1,-40) [-40.0|6513.5] "C" Vector__XXX
 SG_ module2Cell13Temperature_C : 39|16@0+ (0.1,-40) [-40.0|6513.5] "C" Vector__XXX
 SG_ module2Cell14Temperature_C : 55|16@0+ (0.1,-40) [-40.0|6513.5] "C" Vector__XXX

BO_ 816 ID_816: 8 Vector__XXX
 SG_ module3MaxCellVoltage_V : 7|16@0+ (0.001,0) [0.0|65.535] "V" Vector__XXX
 SG_ module3MinCellVoltage_V : 23|16@0+ (0.001,0) [0.0|65.535] "V" Vector__XXX
 SG_ module3AvgCellVoltage_V : 39|16@0+ (0.001,0) [0.0|65.535] "V" Vector__XXX
 SG_ module3DieTemperature_C : 55|16@0+ (0.1,-40) [-40.0|6513.5] "C" Vector__XXX

BO_ 817 ID_817: 8 Vector__XXX
 SG_ module3MaxCellTemperature_C : 7|16@0+ (0.1,-40) [-40.0|6513.5] "C" Vector__XXX
 SG_ module3MinCellTemperature_C : 23|16@0+ (0.1,-40) [-40.0|6513.5] "C" Vector__XXX
 SG_ module3AvgCellTemperature_C : 39|16@0+ (0.1,-40) [-40.0|6513.5] "C" Vector__XXX
 SG_ module3BoardTemperature_C : 55|16@0+ (0.1,-40) [-40.0|6513.5] "C" Vector__XXX

BO_ 818 ID_818: 8 Vector__XXX
 SG_ module3Cell1Voltage_V : 7|16@0+ (0.001,0) [0.0|65.535] "V" Vector__XXX
 SG_ module3Cell2Voltage_V : 23|16@0+ (0.001,0) [0.0|65.535] "V" Vector__XXX
 SG_ module3Cell3Voltage_V : 39|16@0+ (0.001,0) [0.0|65.535] "V" Vector__XXX
 SG_ module3Cell4Voltage_V : 55|16@0+ (0.001,0) [0.0|65.535] "V" Vector__XXX

BO_ 819 ID_819: 8 Vector__XXX
 SG_ module3Cell5Voltage_V : 7|16@0+ (0.001,0) [0.0|65.535] "V" Vector__XXX
 SG_ module3Cell6Voltage_V : 23|16@0+ (0.001,0) [0.0|65.535] "V" Vector__XXX
 SG_ module3Cell7Voltage_V : 39|16@0+ (0.001,0) [0.0|65.535] "V" Vector__XXX
 SG_ module3Cell8Voltage_V : 55|16@0+ (0.001,0) [0.0|65.535] "V" Vector__XXX

BO_ 820 ID_820: 8 Vector__XXX
 SG_ module3Cell9Voltage_V : 7|16@0+ (0.001,0) [0.0|65.535] "V" Vector__XXX
 SG_ module3Cell10Voltage_V : 23|16@0+ (0.001,0) [0.0|65.535] "V" Vector__XXX
 SG_ module3Cell11Voltage_V : 39|16@0+ (0.001,0) [0.0|65.535] "V" Vector__XXX
 SG_ module3Cell12Voltage_V : 55|16@0+ (0.001,0) [0.0|65.535] "V" Vector__XXX

BO_ 821 ID_821: 8 Vector__XXX
 SG_ module3Cell13Voltage_V : 7|16@0+ (0.001,0) [0.0|65.535] "V" Vector__XXX
 SG_ module3Cell14Voltage_V : 23|16@0+ (0.001,0) [0.0|65.535] "V" Vector__XXX
 SG_ module3Cell1Temperature_C : 39|16@0+ (0.1,-40) [-40.0|6513.5] "C" Vector__XXX
 SG_ module3Cell2Temperature_C : 55|16@0+ (0.1,-40) [-40.0|6513.5] "C" Vector__XXX

BO_ 822 ID_822: 8 Vector__XXX
 SG_ module3Cell3Temperature_C : 7|16@0+ (0.1,-40) [-40.0|6513.5] "C" Vector__XXX
 SG_ module3Cell4Temperature_C : 23|16@0+ (0.1,-40) [-40.0|6513.5] "C" Vector__XXX
 SG_ module3Cell5Temperature_C : 39|16@0+ (0.1,-40) [-40.0|6513.5] "C" Vector__XXX
 SG_ module3Cell6Temperature_C : 55|16@0+ (0.1,-40) [-40.0|6513.5] "C" Vector__XXX

BO_ 823 ID_823: 8 Vector__XXX
 SG_ module3Cell7Temperature_C : 7|16@0+ (0.1,-40) [-40.0|6513.5] "C" Vector__XXX
 SG_ module3Cell8Temperature_C : 23|16@0+ (0.1,-40) [-40.0|6513.5] "C" Vector__XXX
 SG_ module3Cell9Temperature_C : 39|16@0+ (0.1,-40) [-40.0|6513.5] "C" Vector__XXX
 SG_ module3Cell10Temperature_C : 55|16@0+ (0.1,-40) [-40.0|6513.5] "C" Vector__XXX

BO_ 824 ID_824: 8 Vector__XXX
 SG_ module3Cell11Temperature_C : 7|16@0+ (0.1,-40) [-40.0|6513.5] "C" Vector__XXX
 SG_ module3Cell12Temperature_C : 23|16@0+ (0.1,-40) [-40.0|6513.5] "C" Vector__XXX
 SG_ module3Cell13Temperature_C : 39|16@0+ (0.1,-40) [-40.0|6513.5] "C" Vector__XXX
 SG_ module3Cell14Temperature_C : 55|16@0+ (0.1,-40) [-40.0|6513.5] "C" Vector__XXX

BO_ 832 ID_832: 8 Vector__XXX
 SG_ module4MaxCellVoltage_V : 7|16@0+ (0.001,0) [0.0|65.535] "V" Vector__XXX
 SG_ module4MinCellVoltage_V : 23|16@0+ (0.001,0) [0.0|65.535] "V" Vector__XXX
 SG_ module4AvgCellVoltage_V : 39|16@0+ (0.001,0) [0.0|65.535] "V" Vector__XXX
 SG_ module4DieTemperature_C : 55|16@0+ (0.1,-40) [-40.0|6513.5] "C" Vector__XXX

BO_ 833 ID_833: 8 Vector__XXX
 SG_ module4MaxCellTemperature_C : 7|16@0+ (0.1,-40) [-40.0|6513.5] "C" Vector__XXX
 SG_ module4MinCellTemperature_C : 23|16@0+ (0.1,-40) [-40.0|6513.5] "C" Vector__XXX
 SG_ module4AvgCellTemperature_C : 39|16@0+ (0.1,-40) [-40.0|6513.5] "C" Vector__XXX
 SG_ module4BoardTemperature_C : 55|16@0+ (0.1,-40) [-40.0|6513.5] "C" Vector__XXX

BO_ 834 ID_834: 8 Vector__XXX
 SG_ module4Cell1Voltage_V : 7|16@0+ (0.001,0) [0.0|65.535] "V" Vector__XXX
 SG_ module4Cell2Voltage_V : 23|16@0+ (0.001,0) [0.0|65.535] "V" Vector__XXX
 SG_ module4Cell3Voltage_V : 39|16@0+ (0.001,0) [0.0|65.535] "V" Vector__XXX
 SG_ module4Cell4Voltage_V : 55|16@0+ (0.001,0) [0.0|65.535] "V" Vector__XXX

BO_ 835 ID_835: 8 Vector__XXX
 SG_ module4Cell5Voltage_V : 7|16@0+ (0.001,0) [0.0|65.535] "V" Vector__XXX
 SG_ module4Cell6Voltage_V : 23|16@0+ (0.001,0) [0.0|65.535] "V" Vector__XXX
 SG_ module4Cell7Voltage_V : 39|16@0+ (0.001,0) [0.0|65.535] "V" Vector__XXX
 SG_ module4Cell8Voltage_V : 55|16@0+ (0.001,0) [0.0|65.535] "V" Vector__XXX

BO_ 836 ID_836: 8 Vector__XXX
 SG_ module4Cell9Voltage_V : 7|16@0+ (0.001,0) [0.0|65.535] "V" Vector__XXX
 SG_ module4Cell10Voltage_V : 23|16@0+ (0.001,0) [0.0|65.535] "V" Vector__XXX
 SG_ module4Cell11Voltage_V : 39|16@0+ (0.001,0) [0.0|65.535] "V" Vector__XXX
 SG_ module4Cell12Voltage_V : 55|16@0+ (0.001,0) [0.0|65.535] "V" Vector__XXX

BO_ 837 ID_837: 8 Vector__XXX
 SG_ module4Cell13Voltage_V : 7|16@0+ (0.001,0) [0.0|65.535] "V" Vector__XXX
 SG_ module4Cell14Voltage_V : 23|16@0+ (0.001,0) [0.0|65.535] "V" Vector__XXX
 SG_ module4Cell1Temperature_C : 39|16@0+ (0.1,-40) [-40.0|6513.5] "C" Vector__XXX
 SG_ module4Cell2Temperature_C : 55|16@0+ (0.1,-40) [-40.0|6513.5] "C" Vector__XXX

BO_ 838 ID_838: 8 Vector__XXX
 SG_ module4Cell3Temperature_C : 7|16@0+ (0.1,-40) [-40.0|6513.5] "C" Vector__XXX
 SG_ module4Cell4Temperature_C : 23|16@0+ (0.1,-40) [-40.0|6513.5] "C" Vector__XXX
 SG_ module4Cell5Temperature_C : 39|16@0+ (0.1,-40) [-40.0|6513.5] "C" Vector__XXX
 SG_ module4Cell6Temperature_C : 55|16@0+ (0.1,-40) [-40.0|6513.5] "C" Vector__XXX

BO_ 839 ID_839: 8 Vector__XXX
 SG_ module4Cell7Temperature_C : 7|16@0+ (0.1,-40) [-40.0|6513.5] "C" Vector__XXX
 SG_ module4Cell8Temperature_C : 23|16@0+ (0.1,-40) [-40.0|6513.5] "C" Vector__XXX
 SG_ module4Cell9Temperature_C : 39|16@0+ (0.1,-40) [-40.0|6513.5] "C" Vector__XXX
 SG_ module4Cell10Temperature_C : 55|16@0+ (0.1,-40) [-40.0|6513.5] "C" Vector__XXX

BO_ 840 ID_840: 8 Vector__XXX
 SG_ module4Cell11Temperature_C : 7|16@0+ (0.1,-40) [-40.0|6513.5] "C" Vector__XXX
 SG_ module4Cell12Temperature_C : 23|16@0+ (0.1,-40) [-40.0|6513.5] "C" Vector__XXX
 SG_ module4Cell13Temperature_C : 39|16@0+ (0.1,-40) [-40.0|6513.5] "C" Vector__XXX
 SG_ module4Cell14Temperature_C : 55|16@0+ (0.1,-40) [-40.0|6513.5] "C" Vector__XXX

BO_ 848 ID_848: 8 Vector__XXX
 SG_ module5MaxCellVoltage_V : 7|16@0+ (0.001,0) [0.0|65.535] "V" Vector__XXX
 SG_ module5MinCellVoltage_V : 23|16@0+ (0.001,0) [0.0|65.535] "V" Vector__XXX
 SG_ module5AvgCellVoltage_V : 39|16@0+ (0.001,0) [0.0|65.535] "V" Vector__XXX
 SG_ module5DieTemperature_C : 55|16@0+ (0.1,-40) [-40.0|6513.5] "C" Vector__XXX

BO_ 849 ID_849: 8 Vector__XXX
 SG_ module5MaxCellTemperature_C : 7|16@0+ (0.1,-40) [-40.0|6513.5] "C" Vector__XXX
 SG_ module5MinCellTemperature_C : 23|16@0+ (0.1,-40) [-40.0|6513.5] "C" Vector__XXX
 SG_ module5AvgCellTemperature_C : 39|16@0+ (0.1,-40) [-40.0|6513.5] "C" Vector__XXX
 SG_ module5BoardTemperature_C : 55|16@0+ (0.1,-40) [-40.0|6513.5] "C" Vector__XXX

BO_ 850 ID_850: 8 Vector__XXX
 SG_ module5Cell1Voltage_V : 7|16@0+ (0.001,0) [0.0|65.535] "V" Vector__XXX
 SG_ module5Cell2Voltage_V : 23|16@0+ (0.001,0) [0.0|65.535] "V" Vector__XXX
 SG_ module5Cell3Voltage_V : 39|16@0+ (0.001,0) [0.0|65.535] "V" Vector__XXX
 SG_ module5Cell4Voltage_V : 55|16@0+ (0.001,0) [0.0|65.535] "V" Vector__XXX

BO_ 851 ID_851: 8 Vector__XXX
 SG_ module5Cell5Voltage_V : 7|16@0+ (0.001,0) [0.0|65.535] "V" Vector__XXX
 SG_ module5Cell6Voltage_V : 23|16@0+ (0.001,0) [0.0|65.535] "V" Vector__XXX
 SG_ module5Cell7Voltage_V : 39|16@0+ (0.001,0) [0.0|65.535] "V" Vector__XXX
 SG_ module5Cell8Voltage_V : 55|16@0+ (0.001,0) [0.0|65.535] "V" Vector__XXX

BO_ 852 ID_852: 8 Vector__XXX
 SG_ module5Cell9Voltage_V : 7|16@0+ (0.001,0) [0.0|65.535] "V" Vector__XXX
 SG_ module5Cell10Voltage_V : 23|16@0+ (0.001,0) [0.0|65.535] "V" Vector__XXX
 SG_ module5Cell11Voltage_V : 39|16@0+ (0.001,0) [0.0|65.535] "V" Vector__XXX
 SG_ module5Cell12Voltage_V : 55|16@0+ (0.001,0) [0.0|65.535] "V" Vector__XXX

BO_ 853 ID_853: 8 Vector__XXX
 SG_ module5Cell13Voltage_V : 7|16@0+ (0.001,0) [0.0|65.535] "V" Vector__XXX
 SG_ module5Cell14Voltage_V : 23|16@0+ (0.001,0) [0.0|65.535] "V" Vector__XXX
 SG_ module5Cell1Temperature_C : 39|16@0+ (0.1,-40) [-40.0|6513.5] "C" Vector__XXX
 SG_ module5Cell2Temperature_C : 55|16@0+ (0.1,-40) [-40.0|6513.5] "C" Vector__XXX

BO_ 854 ID_854: 8 Vector__XXX
 SG_ module5Cell3Temperature_C : 7|16@0+ (0.1,-40) [-40.0|6513.5] "C" Vector__XXX
 SG_ module5Cell4Temperature_C : 23|16@0+ (0.1,-40) [-40.0|6513.5] "C" Vector__XXX
 SG_ module5Cell5Temperature_C : 39|16@0+ (0.1,-40) [-40.0|6513.5] "C" Vector__XXX
 SG_ module5Cell6Temperature_C : 55|16@0+ (0.1,-40) [-40.0|6513.5] "C" Vector__XXX

BO_ 855 ID_855: 8 Vector__XXX
 SG_ module5Cell7Temperature_C : 7|16@0+ (0.1,-40) [-40.0|6513.5] "C" Vector__XXX
 SG_ module5Cell8Temperature_C : 23|16@0+ (0.1,-40) [-40.0|6513.5] "C" Vector__XXX
 SG_ module5Cell9Temperature_C : 39|16@0+ (0.1,-40) [-40.0|6513.5] "C" Vector__XXX
 SG_ module5Cell10Temperature_C : 55|16@0+ (0.1,-40) [-40.0|6513.5] "C" Vector__XXX

BO_ 856 ID_856: 8 Vector__XXX
 SG_ module5Cell11Temperature_C : 7|16@0+ (0.1,-40) [-40.0|6513.5] "C" Vector__XXX
 SG_ module5Cell12Temperature_C : 23|16@0+ (0.1,-40) [-40.0|6513.5] "C" Vector__XXX
 SG_ module5Cell13Temperature_C : 39|16@0+ (0.1,-40) [-40.0|6513.5] "C" Vector__XXX
 SG_ module5Cell14Temperature_C : 55|16@0+ (0.1,-40) [-40.0|6513.5] "C" Vector__XXX

BO_ 864 ID_864: 8 Vector__XXX
 SG_ module6MaxCellVoltage_V : 7|16@0+ (0.001,0) [0.0|65.535] "V" Vector__XXX
 SG_ module6MinCellVoltage_V : 23|16@0+ (0.001,0) [0.0|65.535] "V" Vector__XXX
 SG_ module6AvgCellVoltage_V : 39|16@0+ (0.001,0) [0.0|65.535] "V" Vector__XXX
 SG_ module6DieTemperature_C : 55|16@0+ (0.1,-40) [-40.0|6513.5] "C" Vector__XXX

BO_ 865 ID_865: 8 Vector__XXX
 SG_ module6MaxCellTemperature_C : 7|16@0+ (0.1,-40) [-40.0|6513.5] "C" Vector__XXX
 SG_ module6MinCellTemperature_C : 23|16@0+ (0.1,-40) [-40.0|6513.5] "C" Vector__XXX
 SG_ module6AvgCellTemperature_C : 39|16@0+ (0.1,-40) [-40.0|6513.5] "C" Vector__XXX
 SG_ module6BoardTemperature_C : 55|16@0+ (0.1,-40) [-40.0|6513.5] "C" Vector__XXX

BO_ 866 ID_866: 8 Vector__XXX
 SG_ module6Cell1Voltage_V : 7|16@0+ (0.001,0) [0.0|65.535] "V" Vector__XXX
 SG_ module6Cell2Voltage_V : 23|16@0+ (0.001,0) [0.0|65.535] "V" Vector__XXX
 SG_ module6Cell3Voltage_V : 39|16@0+ (0.001,0) [0.0|65.535] "V" Vector__XXX
 SG_ module6Cell4Voltage_V : 55|16@0+ (0.001,0) [0.0|65.535] "V" Vector__XXX

BO_ 867 ID_867: 8 Vector__XXX
 SG_ module6Cell5Voltage_V : 7|16@0+ (0.001,0) [0.0|65.535] "V" Vector__XXX
 SG_ module6Cell6Voltage_V : 23|16@0+ (0.001,0) [0.0|65.535] "V" Vector__XXX
 SG_ module6Cell7Voltage_V : 39|16@0+ (0.001,0) [0.0|65.535] "V" Vector__XXX
 SG_ module6Cell8Voltage_V : 55|16@0+ (0.001,0) [0.0|65.535] "V" Vector__XXX

BO_ 868 ID_868: 8 Vector__XXX
 SG_ module6Cell9Voltage_V : 7|16@0+ (0.001,0) [0.0|65.535] "V" Vector__XXX
 SG_ module6Cell10Voltage_V : 23|16@0+ (0.001,0) [0.0|65.535] "V" Vector__XXX
 SG_ module6Cell11Voltage_V : 39|16@0+ (0.001,0) [0.0|65.535] "V" Vector__XXX
 SG_ module6Cell12Voltage_V : 55|16@0+ (0.001,0) [0.0|65.535] "V" Vector__XXX

BO_ 869 ID_869: 8 Vector__XXX
 SG_ module6Cell13Voltage_V : 7|16@0+ (0.001,0) [0.0|65.535] "V" Vector__XXX
 SG_ module6Cell14Voltage_V : 23|16@0+ (0.001,0) [0.0|65.535] "V" Vector__XXX
 SG_ module6Cell1Temperature_C : 39|16@0+ (0.1,-40) [-40.0|6513.5] "C" Vector__XXX
 SG_ module6Cell2Temperature_C : 55|16@0+ (0.1,-40) [-40.0|6513.5] "C" Vector__XXX

BO_ 870 ID_870: 8 Vector__XXX
 SG_ module6Cell3Temperature_C : 7|16@0+ (0.1,-40) [-40.0|6513.5] "C" Vector__XXX
 SG_ module6Cell4Temperature_C : 23|16@0+ (0.1,-40) [-40.0|6513.5] "C" Vector__XXX
 SG_ module6Cell5Temperature_C : 39|16@0+ (0.1,-40) [-40.0|6513.5] "C" Vector__XXX
 SG_ module6Cell6Temperature_C : 55|16@0+ (0.1,-40) [-40.0|6513.5] "C" Vector__XXX

BO_ 871 ID_871: 8 Vector__XXX
 SG_ module6Cell7Temperature_C : 7|16@0+ (0.1,-40) [-40.0|6513.5] "C" Vector__XXX
 SG_ module6Cell8Temperature_C : 23|16@0+ (0.1,-40) [-40.0|6513.5] "C" Vector__XXX
 SG_ module6Cell9Temperature_C : 39|16@0+ (0.1,-40) [-40.0|6513.5] "C" Vector__XXX
 SG_ module6Cell10Temperature_C : 55|16@0+ (0.1,-40) [-40.0|6513.5] "C" Vector__XXX

BO_ 872 ID_872: 8 Vector__XXX
 SG_ module6Cell11Temperature_C : 7|16@0+ (0.1,-40) [-40.0|6513.5] "C" Vector__XXX
 SG_ module6Cell12Temperature_C : 23|16@0+ (0.1,-40) [-40.0|6513.5] "C" Vector__XXX
 SG_ module6Cell13Temperature_C : 39|16@0+ (0.1,-40) [-40.0|6513.5] "C" Vector__XXX
 SG_ module6Cell14Temperature_C : 55|16@0+ (0.1,-40) [-40.0|6513.5] "C" Vector__XXX

BO_ 880 ID_880: 8 Vector__XXX
 SG_ module7MaxCellVoltage_V : 7|16@0+ (0.001,0) [0.0|65.535] "V" Vector__XXX
 SG_ module7MinCellVoltage_V : 23|16@0+ (0.001,0) [0.0|65.535] "V" Vector__XXX
 SG_ module7AvgCellVoltage_V : 39|16@0+ (0.001,0) [0.0|65.535] "V" Vector__XXX
 SG_ module7DieTemperature_C : 55|16@0+ (0.1,-40) [-40.0|6513.5] "C" Vector__XXX

BO_ 881 ID_881: 8 Vector__XXX
 SG_ module7MaxCellTemperature_C : 7|16@0+ (0.1,-40) [-40.0|6513.5] "C" Vector__XXX
 SG_ module7MinCellTemperature_C : 23|16@0+ (0.1,-40) [-40.0|6513.5] "C" Vector__XXX
 SG_ module7AvgCellTemperature_C : 39|16@0+ (0.1,-40) [-40.0|6513.5] "C" Vector__XXX
 SG_ module7BoardTemperature_C : 55|16@0+ (0.1,-40) [-40.0|6513.5] "C" Vector__XXX

BO_ 882 ID_882: 8 Vector__XXX
 SG_ module7Cell1Voltage_V : 7|16@0+ (0.001,0) [0.0|65.535] "V" Vector__XXX
 SG_ module7Cell2Voltage_V : 23|16@0+ (0.001,0) [0.0|65.535] "V" Vector__XXX
 SG_ module7Cell3Voltage_V : 39|16@0+ (0.001,0) [0.0|65.535] "V" Vector__XXX
 SG_ module7Cell4Voltage_V : 55|16@0+ (0.001,0) [0.0|65.535] "V" Vector__XXX

BO_ 883 ID_883: 8 Vector__XXX
 SG_ module7Cell5Voltage_V : 7|16@0+ (0.001,0) [0.0|65.535] "V" Vector__XXX
 SG_ module7Cell6Voltage_V : 23|16@0+ (0.001,0) [0.0|65.535] "V" Vector__XXX
 SG_ module7Cell7Voltage_V : 39|16@0+ (0.001,0) [0.0|65.535] "V" Vector__XXX
 SG_ module7Cell8Voltage_V : 55|16@0+ (0.001,0) [0.0|65.535] "V" Vector__XXX

BO_ 884 ID_884: 8 Vector__XXX
 SG_ module7Cell9Voltage_V : 7|16@0+ (0.001,0) [0.0|65.535] "V" Vector__XXX
 SG_ module7Cell10Voltage_V : 23|16@0+ (0.001,0) [0.0|65.535] "V" Vector__XXX
 SG_ module7Cell11Voltage_V : 39|16@0+ (0.001,0) [0.0|65.535] "V" Vector__XXX
 SG_ module7Cell12Voltage_V : 55|16@0+ (0.001,0) [0.0|65.535] "V" Vector__XXX

BO_ 885 ID_885: 8 Vector__XXX
 SG_ module7Cell13Voltage_V : 7|16@0+ (0.001,0) [0.0|65.535] "V" Vector__XXX
 SG_ module7Cell14Voltage_V : 23|16@0+ (0.001,0) [0.0|65.535] "V" Vector__XXX
 SG_ module7Cell1Temperature_C : 39|16@0+ (0.1,-40) [-40.0|6513.5] "C" Vector__XXX
 SG_ module7Cell2Temperature_C : 55|16@0+ (0.1,-40) [-40.0|6513.5] "C" Vector__XXX

BO_ 886 ID_886: 8 Vector__XXX
 SG_ module7Cell3Temperature_C : 7|16@0+ (0.1,-40) [-40.0|6513.5] "C" Vector__XXX
 SG_ module7Cell4Temperature_C : 23|16@0+ (0.1,-40) [-40.0|6513.5] "C" Vector__XXX
 SG_ module7Cell5Temperature_C : 39|16@0+ (0.1,-40) [-40.0|6513.5] "C" Vector__XXX
 SG_ module7Cell6Temperature_C : 55|16@0+ (0.1,-40) [-40.0|6513.5] "C" Vector__XXX

BO_ 887 ID_887: 8 Vector__XXX
 SG_ module7Cell7Temperature_C : 7|16@0+ (0.1,-40) [-40.0|6513.5] "C" Vector__XXX
 SG_ module7Cell8Temperature_C : 23|16@0+ (0.1,-40) [-40.0|6513.5] "C" Vector__XXX
 SG_ module7Cell9Temperature_C : 39|16@0+ (0.1,-40) [-40.0|6513.5] "C" Vector__XXX
 SG_ module7Cell10Temperature_C : 55|16@0+ (0.1,-40) [-40.0|6513.5] "C" Vector__XXX

BO_ 888 ID_888: 8 Vector__XXX
 SG_ module7Cell11Temperature_C : 7|16@0+ (0.1,-40) [-40.0|6513.5] "C" Vector__XXX
 SG_ module7Cell12Temperature_C : 23|16@0+ (0.1,-40) [-40.0|6513.5] "C" Vector__XXX
 SG_ module7Cell13Temperature_C : 39|16@0+ (0.1,-40) [-40.0|6513.5] "C" Vector__XXX
 SG_ module7Cell14Temperature_C : 55|16@0+ (0.1,-40) [-40.0|6513.5] "C" Vector__XXX

BO_ 896 ID_896: 8 Vector__XXX
 SG_ module8MaxCellVoltage_V : 7|16@0+ (0.001,0) [0.0|65.535] "V" Vector__XXX
 SG_ module8MinCellVoltage_V : 23|16@0+ (0.001,0) [0.0|65.535] "V" Vector__XXX
 SG_ module8AvgCellVoltage_V : 39|16@0+ (0.001,0) [0.0|65.535] "V" Vector__XXX
 SG_ module8DieTemperature_C : 55|16@0+ (0.1,-40) [-40.0|6513.5] "C" Vector__XXX

BO_ 897 ID_897: 8 Vector__XXX
 SG_ module8MaxCellTemperature_C : 7|16@0+ (0.1,-40) [-40.0|6513.5] "C" Vector__XXX
 SG_ module8MinCellTemperature_C : 23|16@0+ (0.1,-40) [-40.0|6513.5] "C" Vector__XXX
 SG_ module8AvgCellTemperature_C : 39|16@0+ (0.1,-40) [-40.0|6513.5] "C" Vector__XXX
 SG_ module8BoardTemperature_C : 55|16@0+ (0.1,-40) [-40.0|6513.5] "C" Vector__XXX

BO_ 898 ID_898: 8 Vector__XXX
 SG_ module8Cell1Voltage_V : 7|16@0+ (0.001,0) [0.0|65.535] "V" Vector__XXX
 SG_ module8Cell2Voltage_V : 23|16@0+ (0.001,0) [0.0|65.535] "V" Vector__XXX
 SG_ module8Cell3Voltage_V : 39|16@0+ (0.001,0) [0.0|65.535] "V" Vector__XXX
 SG_ module8Cell4Voltage_V : 55|16@0+ (0.001,0) [0.0|65.535] "V" Vector__XXX

BO_ 899 ID_899: 8 Vector__XXX
 SG_ module8Cell5Voltage_V : 7|16@0+ (0.001,0) [0.0|65.535] "V" Vector__XXX
 SG_ module8Cell6Voltage_V : 23|16@0+ (0.001,0) [0.0|65.535] "V" Vector__XXX
 SG_ module8Cell7Voltage_V : 39|16@0+ (0.001,0) [0.0|65.535] "V" Vector__XXX
 SG_ module8Cell8Voltage_V : 55|16@0+ (0.001,0) [0.0|65.535] "V" Vector__XXX

BO_ 900 ID_900: 8 Vector__XXX
 SG_ module8Cell9Voltage_V : 7|16@0+ (0.001,0) [0.0|65.535] "V" Vector__XXX
 SG_ module8Cell10Voltage_V : 23|16@0+ (0.001,0) [0.0|65.535] "V" Vector__XXX
 SG_ module8Cell11Voltage_V : 39|16@0+ (0.001,0) [0.0|65.535] "V" Vector__XXX
 SG_ module8Cell12Voltage_V : 55|16@0+ (0.001,0) [0.0|65.535] "V" Vector__XXX

BO_ 901 ID_901: 8 Vector__XXX
 SG_ module8Cell13Voltage_V : 7|16@0+ (0.001,0) [0.0|65.535] "V" Vector__XXX
 SG_ module8Cell14Voltage_V : 23|16@0+ (0.001,0) [0.0|65.535] "V" Vector__XXX
 SG_ module8Cell1Temperature_C : 39|16@0+ (0.1,-40) [-40.0|6513.5] "C" Vector__XXX
 SG_ module8Cell2Temperature_C : 55|16@0+ (0.1,-40) [-40.0|6513.5] "C" Vector__XXX

BO_ 902 ID_902: 8 Vector__XXX
 SG_ module8Cell3Temperature_C : 7|16@0+ (0.1,-40) [-40.0|6513.5] "C" Vector__XXX
 SG_ module8Cell4Temperature_C : 23|16@0+ (0.1,-40) [-40.0|6513.5] "C" Vector__XXX
 SG_ module8Cell5Temperature_C : 39|16@0+ (0.1,-40) [-40.0|6513.5] "C" Vector__XXX
 SG_ module8Cell6Temperature_C : 55|16@0+ (0.1,-40) [-40.0|6513.5] "C" Vector__XXX

BO_ 903 ID_903: 8 Vector__XXX
 SG_ module8Cell7Temperature_C : 7|16@0+ (0.1,-40) [-40.0|6513.5] "C" Vector__XXX
 SG_ module8Cell8Temperature_C : 23|16@0+ (0.1,-40) [-40.0|6513.5] "C" Vector__XXX
 SG_ module8Cell9Temperature_C : 39|16@0+ (0.1,-40) [-40.0|6513.5] "C" Vector__XXX
 SG_ module8Cell10Temperature_C : 55|16@0+ (0.1,-40) [-40.0|6513.5] "C" Vector__XXX

BO_ 904 ID_904: 8 Vector__XXX
 SG_ module8Cell11Temperature_C : 7|16@0+ (0.1,-40) [-40.0|6513.5] "C" Vector__XXX
 SG_ module8Cell12Temperature_C : 23|16@0+ (0.1,-40) [-40.0|6513.5] "C" Vector__XXX
 SG_ module8Cell13Temperature_C : 39|16@0+ (0.1,-40) [-40.0|6513.5] "C" Vector__XXX
 SG_ module8Cell14Temperature_C : 55|16@0+ (0.1,-40) [-40.0|6513.5] "C" Vector__XXX

BO_ 912 ID_912: 8 Vector__XXX
 SG_ module9MaxCellVoltage_V : 7|16@0+ (0.001,0) [0.0|65.535] "V" Vector__XXX
 SG_ module9MinCellVoltage_V : 23|16@0+ (0.001,0) [0.0|65.535] "V" Vector__XXX
 SG_ module9AvgCellVoltage_V : 39|16@0+ (0.001,0) [0.0|65.535] "V" Vector__XXX
 SG_ module9DieTemperature_C : 55|16@0+ (0.1,-40) [-40.0|6513.5] "C" Vector__XXX

BO_ 913 ID_913: 8 Vector__XXX
 SG_ module9MaxCellTemperature_C : 7|16@0+ (0.1,-40) [-40.0|6513.5] "C" Vector__XXX
 SG_ module9MinCellTemperature_C : 23|16@0+ (0.1,-40) [-40.0|6513.5] "C" Vector__XXX
 SG_ module9AvgCellTemperature_C : 39|16@0+ (0.1,-40) [-40.0|6513.5] "C" Vector__XXX
 SG_ module9BoardTemperature_C : 55|16@0+ (0.1,-40) [-40.0|6513.5] "C" Vector__XXX

BO_ 914 ID_914: 8 Vector__XXX
 SG_ module9Cell1Voltage_V : 7|16@0+ (0.001,0) [0.0|65.535] "V" Vector__XXX
 SG_ module9Cell2Voltage_V : 23|16@0+ (0.001,0) [0.0|65.535] "V" Vector__XXX
 SG_ module9Cell3Voltage_V : 39|16@0+ (0.001,0) [0.0|65.535] "V" Vector__XXX
 SG_ module9Cell4Voltage_V : 55|16@0+ (0.001,0) [0.0|65.535] "V" Vector__XXX

BO_ 915 ID_915: 8 Vector__XXX
 SG_ module9Cell5Voltage_V : 7|16@0+ (0.001,0) [0.0|65.535] "V" Vector__XXX
 SG_ module9Cell6Voltage_V : 23|16@0+ (0.001,0) [0.0|65.535] "V" Vector__XXX
 SG_ module9Cell7Voltage_V : 39|16@0+ (0.001,0) [0.0|65.535] "V" Vector__XXX
 SG_ module9Cell8Voltage_V : 55|16@0+ (0.001,0) [0.0|65.535] "V" Vector__XXX

BO_ 916 ID_916: 8 Vector__XXX
 SG_ module9Cell9Voltage_V : 7|16@0+ (0.001,0) [0.0|65.535] "V" Vector__XXX
 SG_ module9Cell10Voltage_V : 23|16@0+ (0.001,0) [0.0|65.535] "V" Vector__XXX
 SG_ module9Cell11Voltage_V : 39|16@0+ (0.001,0) [0.0|65.535] "V" Vector__XXX
 SG_ module9Cell12Voltage_V : 55|16@0+ (0.001,0) [0.0|65.535] "V" Vector__XXX

BO_ 917 ID_917: 8 Vector__XXX
 SG_ module9Cell13Voltage_V : 7|16@0+ (0.001,0) [0.0|65.535] "V" Vector__XXX
 SG_ module9Cell14Voltage_V : 23|16@0+ (0.001,0) [0.0|65.535] "V" Vector__XXX
 SG_ module9Cell1Temperature_C : 39|16@0+ (0.1,-40) [-40.0|6513.5] "C" Vector__XXX
 SG_ module9Cell2Temperature_C : 55|16@0+ (0.1,-40) [-40.0|6513.5] "C" Vector__XXX

BO_ 918 ID_918: 8 Vector__XXX
 SG_ module9Cell3Temperature_C : 7|16@0+ (0.1,-40) [-40.0|6513.5] "C" Vector__XXX
 SG_ module9Cell4Temperature_C : 23|16@0+ (0.1,-40) [-40.0|6513.5] "C" Vector__XXX
 SG_ module9Cell5Temperature_C : 39|16@0+ (0.1,-40) [-40.0|6513.5] "C" Vector__XXX
 SG_ module9Cell6Temperature_C : 55|16@0+ (0.1,-40) [-40.0|6513.5] "C" Vector__XXX

BO_ 919 ID_919: 8 Vector__XXX
 SG_ module9Cell7Temperature_C : 7|16@0+ (0.1,-40) [-40.0|6513.5] "C" Vector__XXX
 SG_ module9Cell8Temperature_C : 23|16@0+ (0.1,-40) [-40.0|6513.5] "C" Vector__XXX
 SG_ module9Cell9Temperature_C : 39|16@0+ (0.1,-40) [-40.0|6513.5] "C" Vector__XXX
 SG_ module9Cell10Temperature_C : 55|16@0+ (0.1,-40) [-40.0|6513.5] "C" Vector__XXX

BO_ 920 ID_920: 8 Vector__XXX
 SG_ module9Cell11Temperature_C : 7|16@0+ (0.1,-40) [-40.0|6513.5] "C" Vector__XXX
 SG_ module9Cell12Temperature_C : 23|16@0+ (0.1,-40) [-40.0|6513.5] "C" Vector__XXX
 SG_ module9Cell13Temperature_C : 39|16@0+ (0.1,-40) [-40.0|6513.5] "C" Vector__XXX
 SG_ module9Cell14Temperature_C : 55|16@0+ (0.1,-40) [-40.0|6513.5] "C" Vector__XXX

BO_ 1024 ID_1024: 8 Vector__XXX
 SG_ module10MaxCellVoltage_V : 7|16@0+ (0.001,0) [0.0|65.535] "V" Vector__XXX
 SG_ module10MinCellVoltage_V : 23|16@0+ (0.001,0) [0.0|65.535] "V" Vector__XXX
 SG_ module10AvgCellVoltage_V : 39|16@0+ (0.001,0) [0.0|65.535] "V" Vector__XXX
 SG_ module10DieTemperature_C : 55|16@0+ (0.1,-40) [-40.0|6513.5] "C" Vector__XXX

BO_ 1025 ID_1025: 8 Vector__XXX
 SG_ module10MaxCellTemperature_C : 7|16@0+ (0.1,-40) [-40.0|6513.5] "C" Vector__XXX
 SG_ module10MinCellTemperature_C : 23|16@0+ (0.1,-40) [-40.0|6513.5] "C" Vector__XXX
 SG_ module10AvgCellTemperature_C : 39|16@0+ (0.1,-40) [-40.0|6513.5] "C" Vector__XXX
 SG_ module10BoardTemperature_C : 55|16@0+ (0.1,-40) [-40.0|6513.5] "C" Vector__XXX

BO_ 1026 ID_1026: 8 Vector__XXX
 SG_ module10Cell1Voltage_V : 7|16@0+ (0.001,0) [0.0|65.535] "V" Vector__XXX
 SG_ module10Cell2Voltage_V : 23|16@0+ (0.001,0) [0.0|65.535] "V" Vector__XXX
 SG_ module10Cell3Voltage_V : 39|16@0+ (0.001,0) [0.0|65.535] "V" Vector__XXX
 SG_ module10Cell4Voltage_V : 55|16@0+ (0.001,0) [0.0|65.535] "V" Vector__XXX

BO_ 1027 ID_1027: 8 Vector__XXX
 SG_ module10Cell5Voltage_V : 7|16@0+ (0.001,0) [0.0|65.535] "V" Vector__XXX
 SG_ module10Cell6Voltage_V : 23|16@0+ (0.001,0) [0.0|65.535] "V" Vector__XXX
 SG_ module10Cell7Voltage_V : 39|16@0+ (0.001,0) [0.0|65.535] "V" Vector__XXX
 SG_ module10Cell8Voltage_V : 55|16@0+ (0.001,0) [0.0|65.535] "V" Vector__XXX

BO_ 1028 ID_1028: 8 Vector__XXX
 SG_ module10Cell9Voltage_V : 7|16@0+ (0.001,0) [0.0|65.535] "V" Vector__XXX
 SG_ module10Cell10Voltage_V : 23|16@0+ (0.001,0) [0.0|65.535] "V" Vector__XXX
 SG_ module10Cell11Voltage_V : 39|16@0+ (0.001,0) [0.0|65.535] "V" Vector__XXX
 SG_ module10Cell12Voltage_V : 55|16@0+ (0.001,0) [0.0|65.535] "V" Vector__XXX

BO_ 1029 ID_1029: 8 Vector__XXX
 SG_ module10Cell13Voltage_V : 7|16@0+ (0.001,0) [0.0|65.535] "V" Vector__XXX
 SG_ module10Cell14Voltage_V : 23|16@0+ (0.001,0) [0.0|65.535] "V" Vector__XXX
 SG_ module10Cell1Temperature_C : 39|16@0+ (0.1,-40) [-40.0|6513.5] "C" Vector__XXX
 SG_ module10Cell2Temperature_C : 55|16@0+ (0.1,-40) [-40.0|6513.5] "C" Vector__XXX

BO_ 1030 ID_1030: 8 Vector__XXX
 SG_ module10Cell3Temperature_C : 7|16@0+ (0.1,-40) [-40.0|6513.5] "C" Vector__XXX
 SG_ module10Cell4Temperature_C : 23|16@0+ (0.1,-40) [-40.0|6513.5] "C" Vector__XXX
 SG_ module10Cell5Temperature_C : 39|16@0+ (0.1,-40) [-40.0|6513.5] "C" Vector__XXX
 SG_ module10Cell6Temperature_C : 55|16@0+ (0.1,-40) [-40.0|6513.5] "C" Vector__XXX

BO_ 1031 ID_1031: 8 Vector__XXX
 SG_ module10Cell7Temperature_C : 7|16@0+ (0.1,-40) [-40.0|6513.5] "C" Vector__XXX
 SG_ module10Cell8Temperature_C : 23|16@0+ (0.1,-40) [-40.0|6513.5] "C" Vector__XXX
 SG_ module10Cell9Temperature_C : 39|16@0+ (0.1,-40) [-40.0|6513.5] "C" Vector__XXX
 SG_ module10Cell10Temperature_C : 55|16@0+ (0.1,-40) [-40.0|6513.5] "C" Vector__XXX

BO_ 1032 ID_1032: 8 Vector__XXX
 SG_ module10Cell11Temperature_C : 7|16@0+ (0.1,-40) [-40.0|6513.5] "C" Vector__XXX
 SG_ module10Cell12Temperature_C : 23|16@0+ (0.1,-40) [-40.0|6513.5] "C" Vector__XXX
 SG_ module10Cell13Temperature_C : 39|16@0+ (0.1,-40) [-40.0|6513.5] "C" Vector__XXX
 SG_ module10Cell14Temperature_C : 55|16@0+ (0.1,-40) [-40.0|6513.5] "C" Vector__XXX

BO_ 1033 ID_1033: 8 Vector__XXX
 SG_ chargerVoltageSetPoint_V : 7|16@0+ (0.1,0) [0.0|6553.5] "V" Vector__XXX
 SG_ chargerCurrentSetPoint_A : 23|16@0+ (0.1,0) [0.0|6553.5] "A" Vector__XXX
 SG_ chargerStatusByte : 39|8@0+ (1,0) [0|255] "" Vector__XXX

BO_ 0 ID_0: 8 Vector__XXX
 SG_ vbatChan0Current_A : 7|16@0+ (0.00741391941,0) [0.0|485.87120853435] "V" Vector__XXX
 SG_ vbatChan1Current_A : 23|16@0+ (0.00741391941,0) [0.0|485.87120853435] "V" Vector__XXX
 SG_ vbatChan2Current_A : 39|16@0+ (0.00741391941,0) [0.0|485.87120853435] "V" Vector__XXX
 SG_ vbatChan3Current_A : 55|16@0+ (0.00741391941,0) [0.0|485.87120853435] "V" Vector__XXX

BO_ 1 ID_1: 8 Vector__XXX
 SG_ vbatChan4Current_A : 7|16@0+ (0.00741391941,0) [0.0|485.87120853435] "V" Vector__XXX
 SG_ vbatChan5Current_A : 23|16@0+ (0.00741391941,0) [0.0|485.87120853435] "V" Vector__XXX
 SG_ vbatChan6Current_A : 39|16@0+ (0.00741391941,0) [0.0|485.87120853435] "V" Vector__XXX
 SG_ fiveVChan0Current_A : 55|16@0+ (0.00196141636,0) [0.0|128.5414211526] "V" Vector__XXX

BO_ 2 ID_2: 8 Vector__XXX
 SG_ fiveVChan1Current_A : 7|16@0+ (0.00196141636,0) [0.0|128.5414211526] "V" Vector__XXX
 SG_ fiveVChan2Current_A : 23|16@0+ (0.00196141636,0) [0.0|128.5414211526] "V" Vector__XXX
 SG_ fiveVChan3Current_A : 39|16@0+ (0.00196141636,0) [0.0|128.5414211526] "V" Vector__XXX
 SG_ can0Utilization_percent : 55|16@0+ (0.1,0) [0.0|6553.5] "%" Vector__XXX

BO_ 3 ID_3: 8 Vector__XXX
 SG_ can1Utilization_percent : 7|16@0+ (0.1,0) [0.0|6553.5] "%" Vector__XXX
 SG_ can2Utilization_percent : 23|16@0+ (0.1,0) [0.0|6553.5] "%" Vector__XXX
 SG_ plmVbatVoltage_V : 39|16@0+ (0.00506178266,0) [0.0|331.7239266231] "V" Vector__XXX
 SG_ plm5VVoltage_V : 55|16@0+ (0.00195457875,0) [0.0|128.09331838125] "V" Vector__XXX

BO_ 4 ID_4: 8 Vector__XXX
 SG_ packetsLogged_ul : 7|32@0+ (1,0) [0|4294967295] "" Vector__XXX
 SG_ packetsDropped_ul : 39|32@0+ (1,0) [0|4294967295] "" Vector__XXX

BO_ 5 ID_5: 8 Vector__XXX
 SG_ storageBufferFill_percent : 7|16@0+ (0.1,0) [0.0|6553.5] "%" Vector__XXX
 SG_ telemetryBufferFill_percent : 23|16@0+ (0.1,0) [0.0|6553.5] "%" Vector__XXX

BO_ 6 ID_6: 8 Vector__XXX
 SG_ PLM_Temp_degrees : 7|16@0+ (0.002518,-40) [-40.0|125.01712999999998] "C" Vector__XXX
 SG_ PLM_Humidity_percent : 23|16@0+ (0.024414,0) [0.0|1599.9714900000001] "%" Vector__XXX
 SG_ PLM_Micro_Temp : 39|16@0+ (0.024414,0) [0.0|1599.9714900000001] "%" Vector__XXX

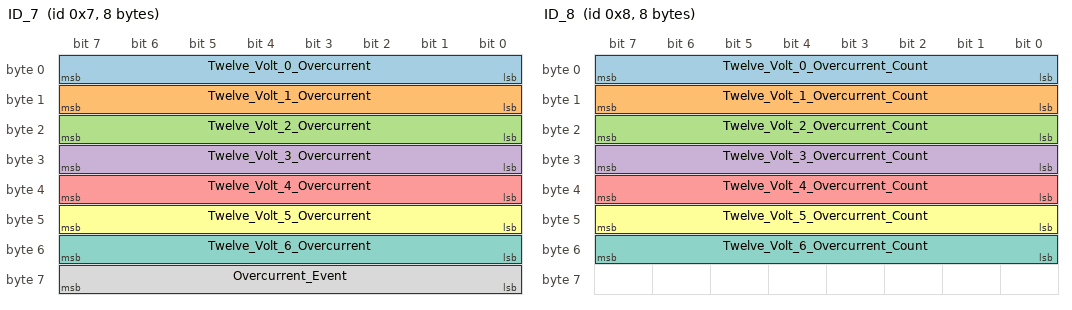
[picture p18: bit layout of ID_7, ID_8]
BO_ 7 ID_7: 8 Vector__XXX
 SG_ Twelve_Volt_0_Overcurrent : 7|8@0+ (1,0) [0|255] "" Vector__XXX
 SG_ Twelve_Volt_1_Overcurrent : 15|8@0+ (1,0) [0|255] "" Vector__XXX
 SG_ Twelve_Volt_2_Overcurrent : 23|8@0+ (1,0) [0|255] "" Vector__XXX
 SG_ Twelve_Volt_3_Overcurrent : 31|8@0+ (1,0) [0|255] "" Vector__XXX
 SG_ Twelve_Volt_4_Overcurrent : 39|8@0+ (1,0) [0|255] "" Vector__XXX
 SG_ Twelve_Volt_5_Overcurrent : 47|8@0+ (1,0) [0|255] "" Vector__XXX
 SG_ Twelve_Volt_6_Overcurrent : 55|8@0+ (1,0) [0|255] "" Vector__XXX
 SG_ Overcurrent_Event : 63|8@0+ (1,0) [0|255] "" Vector__XXX

BO_ 8 ID_8: 8 Vector__XXX
 SG_ Twelve_Volt_0_Overcurrent_Count : 7|8@0+ (1,0) [0|255] "" Vector__XXX
 SG_ Twelve_Volt_1_Overcurrent_Count : 15|8@0+ (1,0) [0|255] "" Vector__XXX
 SG_ Twelve_Volt_2_Overcurrent_Count : 23|8@0+ (1,0) [0|255] "" Vector__XXX
 SG_ Twelve_Volt_3_Overcurrent_Count : 31|8@0+ (1,0) [0|255] "" Vector__XXX
 SG_ Twelve_Volt_4_Overcurrent_Count : 39|8@0+ (1,0) [0|255] "" Vector__XXX
 SG_ Twelve_Volt_5_Overcurrent_Count : 47|8@0+ (1,0) [0|255] "" Vector__XXX
 SG_ Twelve_Volt_6_Overcurrent_Count : 55|8@0+ (1,0) [0|255] "" Vector__XXX

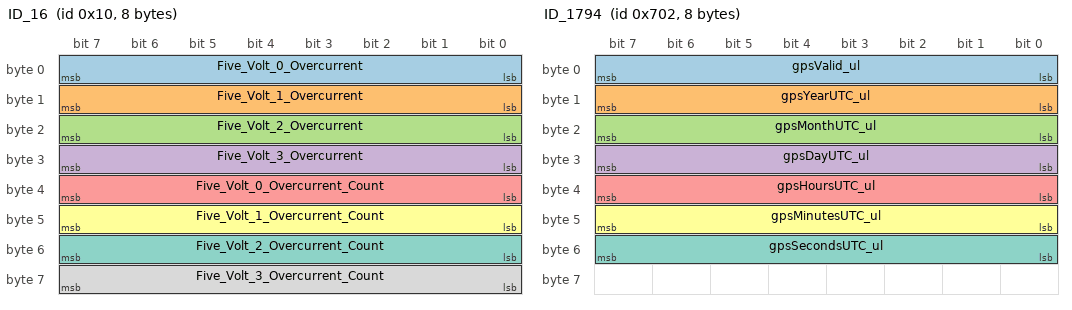
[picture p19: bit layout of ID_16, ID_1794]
BO_ 16 ID_16: 8 Vector__XXX
 SG_ Five_Volt_0_Overcurrent : 7|8@0+ (1,0) [0|255] "" Vector__XXX
 SG_ Five_Volt_1_Overcurrent : 15|8@0+ (1,0) [0|255] "" Vector__XXX
 SG_ Five_Volt_2_Overcurrent : 23|8@0+ (1,0) [0|255] "" Vector__XXX
 SG_ Five_Volt_3_Overcurrent : 31|8@0+ (1,0) [0|255] "" Vector__XXX
 SG_ Five_Volt_0_Overcurrent_Count : 39|8@0+ (1,0) [0|255] "" Vector__XXX
 SG_ Five_Volt_1_Overcurrent_Count : 47|8@0+ (1,0) [0|255] "" Vector__XXX
 SG_ Five_Volt_2_Overcurrent_Count : 55|8@0+ (1,0) [0|255] "" Vector__XXX
 SG_ Five_Volt_3_Overcurrent_Count : 63|8@0+ (1,0) [0|255] "" Vector__XXX

BO_ 17 ID_17: 8 Vector__XXX
 SG_ sdcStatus5 : 7|8@0+ (1,0) [0|255] "" Vector__XXX
 SG_ sdcStatus6 : 15|8@0+ (1,0) [0|255] "" Vector__XXX
 SG_ sdcStatus7 : 23|8@0+ (1,0) [0|255] "" Vector__XXX

BO_ 1792 ID_1792: 8 Vector__XXX
 SG_ gpsLatitude_deg : 7|32@0+ (2.1457672119140625e-05,0) [0.0|92159.99997854233] "deg" Vector__XXX
 SG_ gpsLongitude_deg : 39|32@0+ (2.1457672119140625e-05,0) [0.0|92159.99997854233] "deg" Vector__XXX

BO_ 1793 ID_1793: 8 Vector__XXX
 SG_ gpsSpeed_mph : 7|16@0+ (0.01,0) [0.0|655.35] "mph" Vector__XXX
 SG_ gpsAltitude_ft : 23|16@0+ (1,0) [0|65535] "ft" Vector__XXX
 SG_ gpsCourse_deg : 39|16@0+ (0.01,0) [0.0|655.35] "deg" Vector__XXX
 SG_ gpsSatelliteCount_ul : 55|8@0+ (1,0) [0|255] "" Vector__XXX

BO_ 1794 ID_1794: 8 Vector__XXX
 SG_ gpsValid_ul : 7|8@0+ (1,0) [0|255] "" Vector__XXX
 SG_ gpsYearUTC_ul : 15|8@0+ (1,0) [0|255] "" Vector__XXX
 SG_ gpsMonthUTC_ul : 23|8@0+ (1,0) [0|255] "" Vector__XXX
 SG_ gpsDayUTC_ul : 31|8@0+ (1,0) [0|255] "" Vector__XXX
 SG_ gpsHoursUTC_ul : 39|8@0+ (1,0) [0|255] "" Vector__XXX
 SG_ gpsMinutesUTC_ul : 47|8@0+ (1,0) [0|255] "" Vector__XXX
 SG_ gpsSecondsUTC_ul : 55|8@0+ (1,0) [0|255] "" Vector__XXX

BO_ 112 ID_112: 8 Vector__XXX
 SG_ yawRate_degPerSec : 0|16@1+ (0.005,-163.84) [-163.84|163.835] "deg/s" Vector__XXX
 SG_ lateralAccel_G : 32|16@1+ (0.0001274,-4.1746432) [-4.1746432|4.1745158] "G" Vector__XXX

BO_ 128 ID_128: 8 Vector__XXX
 SG_ rollRate_degPerSec : 0|16@1+ (0.005,-163.84) [-163.84|163.835] "deg/s" Vector__XXX
 SG_ longitudinalAccel_G : 32|16@1+ (0.0001274,-4.1746432) [-4.1746432|4.1745158] "G" Vector__XXX

BO_ 1398 ID_1398: 8 Vector__XXX
 SG_ verticalAccel_G : 32|16@1+ (0.0001274,-4.1746432) [-4.1746432|4.1745158] "G" Vector__XXX

BO_ 229 ID_229: 8 Vector__XXX
 SG_ lapBeaconRaw_ul : 7|24@0+ (1,0) [0|16777215] "" Vector__XXX

BO_ 230 ID_230: 8 Vector__XXX
 SG_ lapBeacon_ul : 7|8@0+ (1,0) [0|255] "" Vector__XXX

BO_ 1200 ID_1200: 8 Vector__XXX
 SG_ rearRightTireTempCh1 : 7|16@0+ (0.1,-100.0) [-100.0|6453.5] "C" Vector__XXX

BO_ 1201 ID_1201: 8 Vector__XXX
 SG_ rearRightTireTempCh5 : 7|16@0+ (0.1,-100.0) [-100.0|6453.5] "C" Vector__XXX
 SG_ rearRightTireTempCh7 : 39|16@0+ (0.1,-100.0) [-100.0|6453.5] "C" Vector__XXX
 SG_ rearRightTireTempCh8 : 55|16@0+ (0.1,-100.0) [-100.0|6453.5] "C" Vector__XXX

BO_ 1202 ID_1202: 8 Vector__XXX
 SG_ rearRightTireTempCh9 : 7|16@0+ (0.1,-100.0) [-100.0|6453.5] "C" Vector__XXX
 SG_ rearRightTireTempCh10 : 23|16@0+ (0.1,-100.0) [-100.0|6453.5] "C" Vector__XXX
 SG_ rearRightTireTempCh12 : 55|16@0+ (0.1,-100.0) [-100.0|6453.5] "C" Vector__XXX

BO_ 1203 ID_1203: 8 Vector__XXX
 SG_ rearRightTireTempCh16 : 55|16@0+ (0.1,-100.0) [-100.0|6453.5] "C" Vector__XXX

BO_ 1208 ID_1208: 8 Vector__XXX
 SG_ frontRightTireTempCh1 : 7|16@0+ (0.1,-100.0) [-100.0|6453.5] "C" Vector__XXX

BO_ 1209 ID_1209: 8 Vector__XXX
 SG_ frontRightTireTempCh5 : 7|16@0+ (0.1,-100.0) [-100.0|6453.5] "C" Vector__XXX
 SG_ frontRightTireTempCh7 : 39|16@0+ (0.1,-100.0) [-100.0|6453.5] "C" Vector__XXX
 SG_ frontRightTireTempCh8 : 55|16@0+ (0.1,-100.0) [-100.0|6453.5] "C" Vector__XXX

BO_ 1210 ID_1210: 8 Vector__XXX
 SG_ frontRightTireTempCh9 : 7|16@0+ (0.1,-100.0) [-100.0|6453.5] "C" Vector__XXX
 SG_ frontRightTireTempCh10 : 23|16@0+ (0.1,-100.0) [-100.0|6453.5] "C" Vector__XXX
 SG_ frontRightTireTempCh12 : 55|16@0+ (0.1,-100.0) [-100.0|6453.5] "C" Vector__XXX

BO_ 1211 ID_1211: 8 Vector__XXX
 SG_ frontRightTireTempCh16 : 55|16@0+ (0.1,-100.0) [-100.0|6453.5] "C" Vector__XXX

BO_ 1212 ID_1212: 8 Vector__XXX
 SG_ frontLeftTireTempCh1 : 7|16@0+ (0.1,-100.0) [-100.0|6453.5] "C" Vector__XXX

BO_ 1213 ID_1213: 8 Vector__XXX
 SG_ frontLeftTireTempCh5 : 7|16@0+ (0.1,-100.0) [-100.0|6453.5] "C" Vector__XXX
 SG_ frontLeftTireTempCh7 : 39|16@0+ (0.1,-100.0) [-100.0|6453.5] "C" Vector__XXX
 SG_ frontLeftTireTempCh8 : 55|16@0+ (0.1,-100.0) [-100.0|6453.5] "C" Vector__XXX

BO_ 1214 ID_1214: 8 Vector__XXX
 SG_ frontLeftTireTempCh9 : 7|16@0+ (0.1,-100.0) [-100.0|6453.5] "C" Vector__XXX
 SG_ frontLeftTireTempCh10 : 23|16@0+ (0.1,-100.0) [-100.0|6453.5] "C" Vector__XXX
 SG_ frontLeftTireTempCh12 : 55|16@0+ (0.1,-100.0) [-100.0|6453.5] "C" Vector__XXX

BO_ 1215 ID_1215: 8 Vector__XXX
 SG_ frontLeftTireTempCh16 : 55|16@0+ (0.1,-100.0) [-100.0|6453.5] "C" Vector__XXX

BO_ 1204 ID_1204: 8 Vector__XXX
 SG_ rearLeftTireTempCh1 : 7|16@0+ (0.1,-100.0) [-100.0|6453.5] "C" Vector__XXX

BO_ 1205 ID_1205: 8 Vector__XXX
 SG_ rearLeftTireTempCh5 : 7|16@0+ (0.1,-100.0) [-100.0|6453.5] "C" Vector__XXX
 SG_ rearLeftTireTempCh7 : 39|16@0+ (0.1,-100.0) [-100.0|6453.5] "C" Vector__XXX
 SG_ rearLeftTireTempCh8 : 55|16@0+ (0.1,-100.0) [-100.0|6453.5] "C" Vector__XXX

BO_ 1206 ID_1206: 8 Vector__XXX
 SG_ rearLeftTireTempCh9 : 7|16@0+ (0.1,-100.0) [-100.0|6453.5] "C" Vector__XXX
 SG_ rearLeftTireTempCh10 : 23|16@0+ (0.1,-100.0) [-100.0|6453.5] "C" Vector__XXX
 SG_ rearLeftTireTempCh12 : 55|16@0+ (0.1,-100.0) [-100.0|6453.5] "C" Vector__XXX

BO_ 1207 ID_1207: 8 Vector__XXX
 SG_ rearLeftTireTempCh16 : 55|16@0+ (0.1,-100.0) [-100.0|6453.5] "C" Vector__XXX

BO_ 1872 ID_1872: 8 Vector__XXX
 SG_ tm_CAN1Util_percent : 7|16@0+ (0.1,0) [0.0|6553.5] "%" Vector__XXX
 SG_ tm_CAN2Util_percent : 23|16@0+ (0.1,0) [0.0|6553.5] "%" Vector__XXX
 SG_ tm_SDBufferFill_percent : 39|16@0+ (0.1,0) [0.0|6553.5] "%" Vector__XXX
 SG_ tm_RadioBufferFill_percent : 55|16@0+ (0.1,0) [0.0|6553.5] "%" Vector__XXX

BO_ 1873 ID_1873: 8 Vector__XXX
 SG_ tm_SDBytesTransferred_bytes : 7|32@0+ (1,0) [0|4294967295] "" Vector__XXX
 SG_ tm_RadioBytesTransferred_bytes : 39|32@0+ (1,0) [0|4294967295] "" Vector__XXX

BO_ 1874 ID_1874: 8 Vector__XXX
 SG_ tm_SDPacketsDropped_ul : 7|32@0+ (1,0) [0|4294967295] "" Vector__XXX
 SG_ tm_RadioPacketsDropped_ul : 39|32@0+ (1,0) [0|4294967295] "" Vector__XXX

BO_ 1875 ID_1875: 8 Vector__XXX
 SG_ tm_CoinBattery_V : 7|16@0+ (0.01,0) [0.0|655.35] "V" Vector__XXX

BO_ 1876 ID_1876: 8 Vector__XXX
 SG_ sdcStatus17 : 7|8@0+ (1,0) [0|255] "" Vector__XXX
 SG_ sdcStatus18 : 15|8@0+ (1,0) [0|255] "" Vector__XXX
 SG_ sdcStatus19 : 23|8@0+ (1,0) [0|255] "" Vector__XXX

BO_ 1877 ID_1877: 8 Vector__XXX
 SG_ chargingPowerLimit : 7|16@0+ (1,0) [0|65535] "" Vector__XXX
 SG_ forceEnableBalancing_state : 23|8@0+ (1,0) [0|255] "" Vector__XXX
